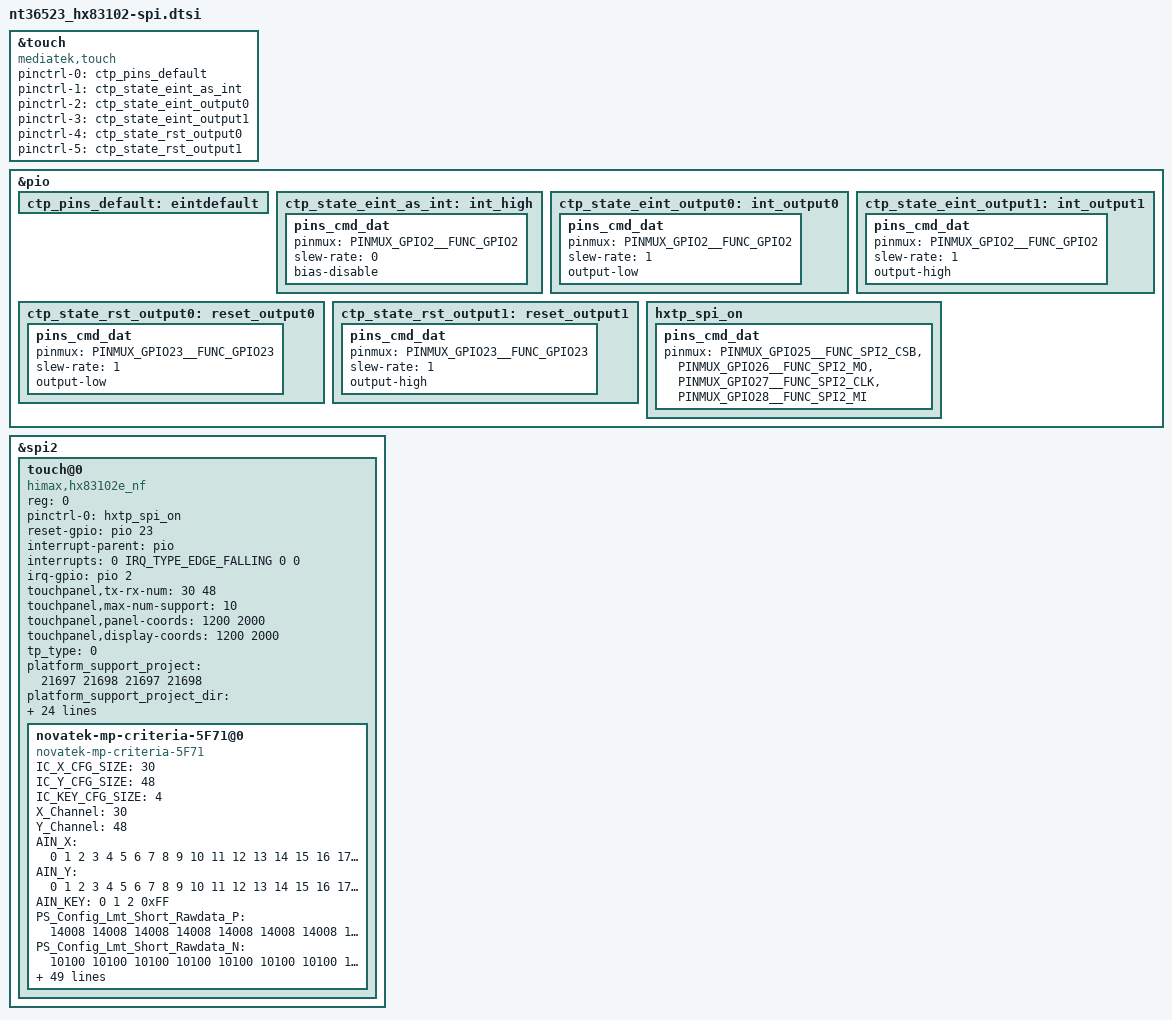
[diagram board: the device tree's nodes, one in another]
/*
 * Copyright (C) 2010 - 2021 Novatek, Inc.
 *
 * $Revision$
 * $Date$
 *
 * This program is free software; you can redistribute it and/or modify
 * it under the terms of the GNU General Public License as published by
 * the Free Software Foundation; either version 2 of the License, or
 * (at your option) any later version.
 *
 * This program is distributed in the hope that it will be useful, but WITHOUT
 * ANY WARRANTY; without even the implied warranty of MERCHANTABILITY or
 * FITNESS FOR A PARTICULAR PURPOSE.  See the GNU General Public License for
 * more details.
 *
 */

&touch {
	compatible = "mediatek,touch";

	pinctrl-names = "default", "state_eint_as_int",
	"state_eint_output0", "state_eint_output1",
	"state_rst_output0", "state_rst_output1";
	pinctrl-0 = <&ctp_pins_default>;
	pinctrl-1 = <&ctp_state_eint_as_int>;
	pinctrl-2 = <&ctp_state_eint_output0>;
	pinctrl-3 = <&ctp_state_eint_output1>;
	pinctrl-4 = <&ctp_state_rst_output0>;
	pinctrl-5 = <&ctp_state_rst_output1>;

};

&pio {

	ctp_pins_default: eintdefault {
	};
	ctp_state_eint_as_int: int_high {
		pins_cmd_dat {
			pinmux = <PINMUX_GPIO2__FUNC_GPIO2>;
			slew-rate = <0>;
			bias-disable;
		};
	};
	ctp_state_eint_output0: int_output0 {
		pins_cmd_dat {
			pinmux = <PINMUX_GPIO2__FUNC_GPIO2>;
			slew-rate = <1>;
			output-low;
		};
	};
	ctp_state_eint_output1: int_output1 {
		pins_cmd_dat {
			pinmux = <PINMUX_GPIO2__FUNC_GPIO2>;
			slew-rate = <1>;
			output-high;
		};
	};
	ctp_state_rst_output0: reset_output0 {
		pins_cmd_dat {
			pinmux = <PINMUX_GPIO23__FUNC_GPIO23>;
			slew-rate = <1>;
			output-low;
		};
	};
	ctp_state_rst_output1: reset_output1 {
		pins_cmd_dat {
			pinmux = <PINMUX_GPIO23__FUNC_GPIO23>;
			slew-rate = <1>;
			output-high;
		};
	};

	hxtp_spi_on:hxtp_spi_on {
	    pins_cmd_dat {
			pinmux = <PINMUX_GPIO25__FUNC_SPI2_CSB>,
			         <PINMUX_GPIO26__FUNC_SPI2_MO>,
					 <PINMUX_GPIO27__FUNC_SPI2_CLK>,
					 <PINMUX_GPIO28__FUNC_SPI2_MI>;

		};
    };
};

&spi2 {
	status = "ok";

	touch@0 {
		compatible = "himax,hx83102e_nf", "novatek,nf_nt36523";

		reg = <0>; //Same as CS ID
		status = "ok";

		/* Himax device*/
		pinctrl-names = "state_spi_all";
		pinctrl-0 = <&hxtp_spi_on>;

		/* Novatek device tree node */
		reset-gpio = <&pio 23 0>;
		interrupt-parent = <&pio>;
		interrupts = <0 IRQ_TYPE_EDGE_FALLING 0 0>; //1 IRQ_TYPE_EDGE_FALLING 1 0
		irq-gpio = <&pio 2 2>;
        //  lcd-reset-gpio = <&pio 44 0>;
		touchpanel,tx-rx-num = <30 48>;
		touchpanel,max-num-support = <10>;
		touchpanel,panel-coords = <1200 2000>;
		touchpanel,display-coords = <1200 2000>;
		//touchpanel,touchmajor-limit = <0 54>;
		tp_type = <0>;
		platform_support_project = <21697 21698 21697 21698>;
		platform_support_project_dir = <21697 21698 21697 21698>;
		platform_support_project_commandline = "nt36523b_hdp_dsi_vdo_dijing","nt36523b_hdp_dsi_vdo_dijing", "hx83_hdp_dsi_vdo_txd", "hx83_hdp_dsi_vdo_txd";
		chip_name = "NT36525B";

		spi-max-frequency = <10000000>;

		incell_screen;
		//fw_edge_limit_support;
		black_gesture_support;
		new_set_irq_wake_support;
		charger_pump_support;
		headset_pump_support;
		//esd_handle_support;
		//spurious_fingerprint_support;
		lcd_trigger_fp_check;
		black_gesture_test_support;
		noflash_support;
		smart_gesture_support;
		//pressure_report_support;
		fw_update_app_support;
		game_switch_support;
		//drlimit_remove_support;
		lcd_trigger_load_tp_fw_support;
		fw_update_in_probe_with_headfile;
		touchpanel,button-type = <4>;
		spi_fast_read_support;

		/* 525 */
		//novatek,swrst-n8-addr = <0x01F01A>;

		/* 672A, 525B, 675, 526, 672C, 523 */
		novatek,swrst-n8-addr = <0x03F0FE>;
		novatek,spi-rd-fast-addr = <0x03F310>;

		/* MP */
		//novatek,mp-support-dt;

		/*for longcheer_P560_Realme 523B INX_DJN10.36" module*/
		novatek-mp-criteria-5F71@0 {
			#address-cells = <1>;
			#size-cells = <0>;
			compatible = "novatek-mp-criteria-5F71";

			/* MP Config */
			IC_X_CFG_SIZE = <30>;
			IC_Y_CFG_SIZE = <48>;
			IC_KEY_CFG_SIZE = <4>;
			X_Channel = <30>;
			Y_Channel = <48>;

			AIN_X = <0 1 2 3 4 5 6 7 8 9 10 11 12 13 14 15 16 17 18 19 20 21 22 23 24 25 26 27 28 29>;
			AIN_Y = <0 1 2 3 4 5 6 7 8 9 10 11 12 13 14 15 16 17 18 19 20 21 22 23 24 25 26 27 28 29 30 31 32 33 34 35 36 37 38 39 40 41 42 43 44 45 46 47>;
			AIN_KEY = <0 1 2 0xFF>;

			/* MP Criteria */
			PS_Config_Lmt_Short_Rawdata_P = <
				14008 14008 14008 14008 14008 14008 14008 14008 14008 14008 14008 14008 14008 14008 14008 14008 14008 14008 14008 14008 14008 14008 14008 14008 14008 14008 14008 14008 14008 14008
				14008 14008 14008 14008 14008 14008 14008 14008 14008 14008 14008 14008 14008 14008 14008 14008 14008 14008 14008 14008 14008 14008 14008 14008 14008 14008 14008 14008 14008 14008
				14008 14008 14008 14008 14008 14008 14008 14008 14008 14008 14008 14008 14008 14008 14008 14008 14008 14008 14008 14008 14008 14008 14008 14008 14008 14008 14008 14008 14008 14008
				14008 14008 14008 14008 14008 14008 14008 14008 14008 14008 14008 14008 14008 14008 14008 14008 14008 14008 14008 14008 14008 14008 14008 14008 14008 14008 14008 14008 14008 14008
				14008 14008 14008 14008 14008 14008 14008 14008 14008 14008 14008 14008 14008 14008 14008 14008 14008 14008 14008 14008 14008 14008 14008 14008 14008 14008 14008 14008 14008 14008
				14008 14008 14008 14008 14008 14008 14008 14008 14008 14008 14008 14008 14008 14008 14008 14008 14008 14008 14008 14008 14008 14008 14008 14008 14008 14008 14008 14008 14008 14008
				14008 14008 14008 14008 14008 14008 14008 14008 14008 14008 14008 14008 14008 14008 14008 14008 14008 14008 14008 14008 14008 14008 14008 14008 14008 14008 14008 14008 14008 14008
				14008 14008 14008 14008 14008 14008 14008 14008 14008 14008 14008 14008 14008 14008 14008 14008 14008 14008 14008 14008 14008 14008 14008 14008 14008 14008 14008 14008 14008 14008
				14008 14008 14008 14008 14008 14008 14008 14008 14008 14008 14008 14008 14008 14008 14008 14008 14008 14008 14008 14008 14008 14008 14008 14008 14008 14008 14008 14008 14008 14008
				14008 14008 14008 14008 14008 14008 14008 14008 14008 14008 14008 14008 14008 14008 14008 14008 14008 14008 14008 14008 14008 14008 14008 14008 14008 14008 14008 14008 14008 14008
				14008 14008 14008 14008 14008 14008 14008 14008 14008 14008 14008 14008 14008 14008 14008 14008 14008 14008 14008 14008 14008 14008 14008 14008 14008 14008 14008 14008 14008 14008
				14008 14008 14008 14008 14008 14008 14008 14008 14008 14008 14008 14008 14008 14008 14008 14008 14008 14008 14008 14008 14008 14008 14008 14008 14008 14008 14008 14008 14008 14008
				14008 14008 14008 14008 14008 14008 14008 14008 14008 14008 14008 14008 14008 14008 14008 14008 14008 14008 14008 14008 14008 14008 14008 14008 14008 14008 14008 14008 14008 14008
				14008 14008 14008 14008 14008 14008 14008 14008 14008 14008 14008 14008 14008 14008 14008 14008 14008 14008 14008 14008 14008 14008 14008 14008 14008 14008 14008 14008 14008 14008
				14008 14008 14008 14008 14008 14008 14008 14008 14008 14008 14008 14008 14008 14008 14008 14008 14008 14008 14008 14008 14008 14008 14008 14008 14008 14008 14008 14008 14008 14008
				14008 14008 14008 14008 14008 14008 14008 14008 14008 14008 14008 14008 14008 14008 14008 14008 14008 14008 14008 14008 14008 14008 14008 14008 14008 14008 14008 14008 14008 14008
				14008 14008 14008 14008 14008 14008 14008 14008 14008 14008 14008 14008 14008 14008 14008 14008 14008 14008 14008 14008 14008 14008 14008 14008 14008 14008 14008 14008 14008 14008
				14008 14008 14008 14008 14008 14008 14008 14008 14008 14008 14008 14008 14008 14008 14008 14008 14008 14008 14008 14008 14008 14008 14008 14008 14008 14008 14008 14008 14008 14008
				14008 14008 14008 14008 14008 14008 14008 14008 14008 14008 14008 14008 14008 14008 14008 14008 14008 14008 14008 14008 14008 14008 14008 14008 14008 14008 14008 14008 14008 14008
				14008 14008 14008 14008 14008 14008 14008 14008 14008 14008 14008 14008 14008 14008 14008 14008 14008 14008 14008 14008 14008 14008 14008 14008 14008 14008 14008 14008 14008 14008
				14008 14008 14008 14008 14008 14008 14008 14008 14008 14008 14008 14008 14008 14008 14008 14008 14008 14008 14008 14008 14008 14008 14008 14008 14008 14008 14008 14008 14008 14008
				14008 14008 14008 14008 14008 14008 14008 14008 14008 14008 14008 14008 14008 14008 14008 14008 14008 14008 14008 14008 14008 14008 14008 14008 14008 14008 14008 14008 14008 14008
				14008 14008 14008 14008 14008 14008 14008 14008 14008 14008 14008 14008 14008 14008 14008 14008 14008 14008 14008 14008 14008 14008 14008 14008 14008 14008 14008 14008 14008 14008
				14008 14008 14008 14008 14008 14008 14008 14008 14008 14008 14008 14008 14008 14008 14008 14008 14008 14008 14008 14008 14008 14008 14008 14008 14008 14008 14008 14008 14008 14008
				14008 14008 14008 14008 14008 14008 14008 14008 14008 14008 14008 14008 14008 14008 14008 14008 14008 14008 14008 14008 14008 14008 14008 14008 14008 14008 14008 14008 14008 14008
				14008 14008 14008 14008 14008 14008 14008 14008 14008 14008 14008 14008 14008 14008 14008 14008 14008 14008 14008 14008 14008 14008 14008 14008 14008 14008 14008 14008 14008 14008
				14008 14008 14008 14008 14008 14008 14008 14008 14008 14008 14008 14008 14008 14008 14008 14008 14008 14008 14008 14008 14008 14008 14008 14008 14008 14008 14008 14008 14008 14008
				14008 14008 14008 14008 14008 14008 14008 14008 14008 14008 14008 14008 14008 14008 14008 14008 14008 14008 14008 14008 14008 14008 14008 14008 14008 14008 14008 14008 14008 14008
				14008 14008 14008 14008 14008 14008 14008 14008 14008 14008 14008 14008 14008 14008 14008 14008 14008 14008 14008 14008 14008 14008 14008 14008 14008 14008 14008 14008 14008 14008
				14008 14008 14008 14008 14008 14008 14008 14008 14008 14008 14008 14008 14008 14008 14008 14008 14008 14008 14008 14008 14008 14008 14008 14008 14008 14008 14008 14008 14008 14008
				14008 14008 14008 14008 14008 14008 14008 14008 14008 14008 14008 14008 14008 14008 14008 14008 14008 14008 14008 14008 14008 14008 14008 14008 14008 14008 14008 14008 14008 14008
				14008 14008 14008 14008 14008 14008 14008 14008 14008 14008 14008 14008 14008 14008 14008 14008 14008 14008 14008 14008 14008 14008 14008 14008 14008 14008 14008 14008 14008 14008
				14008 14008 14008 14008 14008 14008 14008 14008 14008 14008 14008 14008 14008 14008 14008 14008 14008 14008 14008 14008 14008 14008 14008 14008 14008 14008 14008 14008 14008 14008
				14008 14008 14008 14008 14008 14008 14008 14008 14008 14008 14008 14008 14008 14008 14008 14008 14008 14008 14008 14008 14008 14008 14008 14008 14008 14008 14008 14008 14008 14008
				14008 14008 14008 14008 14008 14008 14008 14008 14008 14008 14008 14008 14008 14008 14008 14008 14008 14008 14008 14008 14008 14008 14008 14008 14008 14008 14008 14008 14008 14008
				14008 14008 14008 14008 14008 14008 14008 14008 14008 14008 14008 14008 14008 14008 14008 14008 14008 14008 14008 14008 14008 14008 14008 14008 14008 14008 14008 14008 14008 14008
				14008 14008 14008 14008 14008 14008 14008 14008 14008 14008 14008 14008 14008 14008 14008 14008 14008 14008 14008 14008 14008 14008 14008 14008 14008 14008 14008 14008 14008 14008
				14008 14008 14008 14008 14008 14008 14008 14008 14008 14008 14008 14008 14008 14008 14008 14008 14008 14008 14008 14008 14008 14008 14008 14008 14008 14008 14008 14008 14008 14008
				14008 14008 14008 14008 14008 14008 14008 14008 14008 14008 14008 14008 14008 14008 14008 14008 14008 14008 14008 14008 14008 14008 14008 14008 14008 14008 14008 14008 14008 14008
				14008 14008 14008 14008 14008 14008 14008 14008 14008 14008 14008 14008 14008 14008 14008 14008 14008 14008 14008 14008 14008 14008 14008 14008 14008 14008 14008 14008 14008 14008
				14008 14008 14008 14008 14008 14008 14008 14008 14008 14008 14008 14008 14008 14008 14008 14008 14008 14008 14008 14008 14008 14008 14008 14008 14008 14008 14008 14008 14008 14008
				14008 14008 14008 14008 14008 14008 14008 14008 14008 14008 14008 14008 14008 14008 14008 14008 14008 14008 14008 14008 14008 14008 14008 14008 14008 14008 14008 14008 14008 14008
				14008 14008 14008 14008 14008 14008 14008 14008 14008 14008 14008 14008 14008 14008 14008 14008 14008 14008 14008 14008 14008 14008 14008 14008 14008 14008 14008 14008 14008 14008
				14008 14008 14008 14008 14008 14008 14008 14008 14008 14008 14008 14008 14008 14008 14008 14008 14008 14008 14008 14008 14008 14008 14008 14008 14008 14008 14008 14008 14008 14008
				14008 14008 14008 14008 14008 14008 14008 14008 14008 14008 14008 14008 14008 14008 14008 14008 14008 14008 14008 14008 14008 14008 14008 14008 14008 14008 14008 14008 14008 14008
				14008 14008 14008 14008 14008 14008 14008 14008 14008 14008 14008 14008 14008 14008 14008 14008 14008 14008 14008 14008 14008 14008 14008 14008 14008 14008 14008 14008 14008 14008
				14008 14008 14008 14008 14008 14008 14008 14008 14008 14008 14008 14008 14008 14008 14008 14008 14008 14008 14008 14008 14008 14008 14008 14008 14008 14008 14008 14008 14008 14008
				14008 14008 14008 14008 14008 14008 14008 14008 14008 14008 14008 14008 14008 14008 14008 14008 14008 14008 14008 14008 14008 14008 14008 14008 14008 14008 14008 14008 14008 14008
				14008 14008 14008>;

			PS_Config_Lmt_Short_Rawdata_N = <
				10100 10100 10100 10100 10100 10100 10100 10100 10100 10100 10100 10100 10100 10100 10100 10100 10100 10100 10100 10100 10100 10100 10100 10100 10100 10100 10100 10100 10100 10100
				10100 10100 10100 10100 10100 10100 10100 10100 10100 10100 10100 10100 10100 10100 10100 10100 10100 10100 10100 10100 10100 10100 10100 10100 10100 10100 10100 10100 10100 10100
				10100 10100 10100 10100 10100 10100 10100 10100 10100 10100 10100 10100 10100 10100 10100 10100 10100 10100 10100 10100 10100 10100 10100 10100 10100 10100 10100 10100 10100 10100
				10100 10100 10100 10100 10100 10100 10100 10100 10100 10100 10100 10100 10100 10100 10100 10100 10100 10100 10100 10100 10100 10100 10100 10100 10100 10100 10100 10100 10100 10100
				10100 10100 10100 10100 10100 10100 10100 10100 10100 10100 10100 10100 10100 10100 10100 10100 10100 10100 10100 10100 10100 10100 10100 10100 10100 10100 10100 10100 10100 10100
				10100 10100 10100 10100 10100 10100 10100 10100 10100 10100 10100 10100 10100 10100 10100 10100 10100 10100 10100 10100 10100 10100 10100 10100 10100 10100 10100 10100 10100 10100
				10100 10100 10100 10100 10100 10100 10100 10100 10100 10100 10100 10100 10100 10100 10100 10100 10100 10100 10100 10100 10100 10100 10100 10100 10100 10100 10100 10100 10100 10100
				10100 10100 10100 10100 10100 10100 10100 10100 10100 10100 10100 10100 10100 10100 10100 10100 10100 10100 10100 10100 10100 10100 10100 10100 10100 10100 10100 10100 10100 10100
				10100 10100 10100 10100 10100 10100 10100 10100 10100 10100 10100 10100 10100 10100 10100 10100 10100 10100 10100 10100 10100 10100 10100 10100 10100 10100 10100 10100 10100 10100
				10100 10100 10100 10100 10100 10100 10100 10100 10100 10100 10100 10100 10100 10100 10100 10100 10100 10100 10100 10100 10100 10100 10100 10100 10100 10100 10100 10100 10100 10100
				10100 10100 10100 10100 10100 10100 10100 10100 10100 10100 10100 10100 10100 10100 10100 10100 10100 10100 10100 10100 10100 10100 10100 10100 10100 10100 10100 10100 10100 10100
				10100 10100 10100 10100 10100 10100 10100 10100 10100 10100 10100 10100 10100 10100 10100 10100 10100 10100 10100 10100 10100 10100 10100 10100 10100 10100 10100 10100 10100 10100
				10100 10100 10100 10100 10100 10100 10100 10100 10100 10100 10100 10100 10100 10100 10100 10100 10100 10100 10100 10100 10100 10100 10100 10100 10100 10100 10100 10100 10100 10100
				10100 10100 10100 10100 10100 10100 10100 10100 10100 10100 10100 10100 10100 10100 10100 10100 10100 10100 10100 10100 10100 10100 10100 10100 10100 10100 10100 10100 10100 10100
				10100 10100 10100 10100 10100 10100 10100 10100 10100 10100 10100 10100 10100 10100 10100 10100 10100 10100 10100 10100 10100 10100 10100 10100 10100 10100 10100 10100 10100 10100
				10100 10100 10100 10100 10100 10100 10100 10100 10100 10100 10100 10100 10100 10100 10100 10100 10100 10100 10100 10100 10100 10100 10100 10100 10100 10100 10100 10100 10100 10100
				10100 10100 10100 10100 10100 10100 10100 10100 10100 10100 10100 10100 10100 10100 10100 10100 10100 10100 10100 10100 10100 10100 10100 10100 10100 10100 10100 10100 10100 10100
				10100 10100 10100 10100 10100 10100 10100 10100 10100 10100 10100 10100 10100 10100 10100 10100 10100 10100 10100 10100 10100 10100 10100 10100 10100 10100 10100 10100 10100 10100
				10100 10100 10100 10100 10100 10100 10100 10100 10100 10100 10100 10100 10100 10100 10100 10100 10100 10100 10100 10100 10100 10100 10100 10100 10100 10100 10100 10100 10100 10100
				10100 10100 10100 10100 10100 10100 10100 10100 10100 10100 10100 10100 10100 10100 10100 10100 10100 10100 10100 10100 10100 10100 10100 10100 10100 10100 10100 10100 10100 10100
				10100 10100 10100 10100 10100 10100 10100 10100 10100 10100 10100 10100 10100 10100 10100 10100 10100 10100 10100 10100 10100 10100 10100 10100 10100 10100 10100 10100 10100 10100
				10100 10100 10100 10100 10100 10100 10100 10100 10100 10100 10100 10100 10100 10100 10100 10100 10100 10100 10100 10100 10100 10100 10100 10100 10100 10100 10100 10100 10100 10100
				10100 10100 10100 10100 10100 10100 10100 10100 10100 10100 10100 10100 10100 10100 10100 10100 10100 10100 10100 10100 10100 10100 10100 10100 10100 10100 10100 10100 10100 10100
				10100 10100 10100 10100 10100 10100 10100 10100 10100 10100 10100 10100 10100 10100 10100 10100 10100 10100 10100 10100 10100 10100 10100 10100 10100 10100 10100 10100 10100 10100
				10100 10100 10100 10100 10100 10100 10100 10100 10100 10100 10100 10100 10100 10100 10100 10100 10100 10100 10100 10100 10100 10100 10100 10100 10100 10100 10100 10100 10100 10100
				10100 10100 10100 10100 10100 10100 10100 10100 10100 10100 10100 10100 10100 10100 10100 10100 10100 10100 10100 10100 10100 10100 10100 10100 10100 10100 10100 10100 10100 10100
				10100 10100 10100 10100 10100 10100 10100 10100 10100 10100 10100 10100 10100 10100 10100 10100 10100 10100 10100 10100 10100 10100 10100 10100 10100 10100 10100 10100 10100 10100
				10100 10100 10100 10100 10100 10100 10100 10100 10100 10100 10100 10100 10100 10100 10100 10100 10100 10100 10100 10100 10100 10100 10100 10100 10100 10100 10100 10100 10100 10100
				10100 10100 10100 10100 10100 10100 10100 10100 10100 10100 10100 10100 10100 10100 10100 10100 10100 10100 10100 10100 10100 10100 10100 10100 10100 10100 10100 10100 10100 10100
				10100 10100 10100 10100 10100 10100 10100 10100 10100 10100 10100 10100 10100 10100 10100 10100 10100 10100 10100 10100 10100 10100 10100 10100 10100 10100 10100 10100 10100 10100
				10100 10100 10100 10100 10100 10100 10100 10100 10100 10100 10100 10100 10100 10100 10100 10100 10100 10100 10100 10100 10100 10100 10100 10100 10100 10100 10100 10100 10100 10100
				10100 10100 10100 10100 10100 10100 10100 10100 10100 10100 10100 10100 10100 10100 10100 10100 10100 10100 10100 10100 10100 10100 10100 10100 10100 10100 10100 10100 10100 10100
				10100 10100 10100 10100 10100 10100 10100 10100 10100 10100 10100 10100 10100 10100 10100 10100 10100 10100 10100 10100 10100 10100 10100 10100 10100 10100 10100 10100 10100 10100
				10100 10100 10100 10100 10100 10100 10100 10100 10100 10100 10100 10100 10100 10100 10100 10100 10100 10100 10100 10100 10100 10100 10100 10100 10100 10100 10100 10100 10100 10100
				10100 10100 10100 10100 10100 10100 10100 10100 10100 10100 10100 10100 10100 10100 10100 10100 10100 10100 10100 10100 10100 10100 10100 10100 10100 10100 10100 10100 10100 10100
				10100 10100 10100 10100 10100 10100 10100 10100 10100 10100 10100 10100 10100 10100 10100 10100 10100 10100 10100 10100 10100 10100 10100 10100 10100 10100 10100 10100 10100 10100
				10100 10100 10100 10100 10100 10100 10100 10100 10100 10100 10100 10100 10100 10100 10100 10100 10100 10100 10100 10100 10100 10100 10100 10100 10100 10100 10100 10100 10100 10100
				10100 10100 10100 10100 10100 10100 10100 10100 10100 10100 10100 10100 10100 10100 10100 10100 10100 10100 10100 10100 10100 10100 10100 10100 10100 10100 10100 10100 10100 10100
				10100 10100 10100 10100 10100 10100 10100 10100 10100 10100 10100 10100 10100 10100 10100 10100 10100 10100 10100 10100 10100 10100 10100 10100 10100 10100 10100 10100 10100 10100
				10100 10100 10100 10100 10100 10100 10100 10100 10100 10100 10100 10100 10100 10100 10100 10100 10100 10100 10100 10100 10100 10100 10100 10100 10100 10100 10100 10100 10100 10100
				10100 10100 10100 10100 10100 10100 10100 10100 10100 10100 10100 10100 10100 10100 10100 10100 10100 10100 10100 10100 10100 10100 10100 10100 10100 10100 10100 10100 10100 10100
				10100 10100 10100 10100 10100 10100 10100 10100 10100 10100 10100 10100 10100 10100 10100 10100 10100 10100 10100 10100 10100 10100 10100 10100 10100 10100 10100 10100 10100 10100
				10100 10100 10100 10100 10100 10100 10100 10100 10100 10100 10100 10100 10100 10100 10100 10100 10100 10100 10100 10100 10100 10100 10100 10100 10100 10100 10100 10100 10100 10100
				10100 10100 10100 10100 10100 10100 10100 10100 10100 10100 10100 10100 10100 10100 10100 10100 10100 10100 10100 10100 10100 10100 10100 10100 10100 10100 10100 10100 10100 10100
				10100 10100 10100 10100 10100 10100 10100 10100 10100 10100 10100 10100 10100 10100 10100 10100 10100 10100 10100 10100 10100 10100 10100 10100 10100 10100 10100 10100 10100 10100
				10100 10100 10100 10100 10100 10100 10100 10100 10100 10100 10100 10100 10100 10100 10100 10100 10100 10100 10100 10100 10100 10100 10100 10100 10100 10100 10100 10100 10100 10100
				10100 10100 10100 10100 10100 10100 10100 10100 10100 10100 10100 10100 10100 10100 10100 10100 10100 10100 10100 10100 10100 10100 10100 10100 10100 10100 10100 10100 10100 10100
				10100 10100 10100 10100 10100 10100 10100 10100 10100 10100 10100 10100 10100 10100 10100 10100 10100 10100 10100 10100 10100 10100 10100 10100 10100 10100 10100 10100 10100 10100
				10100 10100 10100>;

			PS_Config_Lmt_Open_Rawdata_P = <
				3719	3725	3752	3743	3840	3774	3698	3634	3423	3539	3518	3518	3621	3743	3775	3673	3572	3586	3596	3704	3662	3592	3493	3340	3407	3448	3439	3514	3634	3570
				3816	3777	3759	3798	3735	3627	3599	3556	3329	3400	3458	3511	3617	3633	3621	3655	3605	3612	3655	3588	3528	3484	3441	3227	3333	3367	3434	3519	3575	3544
				3929	3823	3715	3788	3763	3820	3768	3693	3465	3577	3623	3620	3628	3739	3747	3771	3677	3572	3628	3623	3689	3663	3589	3362	3488	3493	3550	3557	3638	3638
				3857	3810	3777	3808	3827	3724	3630	3605	3382	3480	3487	3560	3624	3752	3553	3708	3668	3612	3665	3693	3585	3536	3487	3285	3381	3425	3470	3550	3654	3512
				4008	3892	3785	3652	3780	3715	3789	3739	3438	3588	3634	3694	3704	3718	3739	3834	3754	3651	3515	3627	3586	3662	3635	3341	3491	3544	3563	3637	3648	3642
				3875	3827	3773	3719	3809	3796	3704	3522	3424	3494	3533	3547	3642	3620	3747	3704	3691	3641	3561	3673	3668	3572	3431	3325	3403	3432	3490	3557	3571	3654
				3838	3914	3815	3684	3571	3704	3654	3652	3364	3515	3600	3659	3742	3696	3684	3670	3761	3691	3564	3445	3563	3529	3553	3301	3420	3511	3572	3616	3633	3621
				3957	3795	3747	3673	3631	3724	3719	3633	3445	3508	3519	3570	3603	3694	3677	3810	3647	3627	3554	3486	3603	3602	3507	3367	3410	3428	3467	3551	3617	3610
				3875	3854	3918	3795	3676	3441	3589	3669	3479	3521	3614	3714	3649	3876	3788	3719	3698	3775	3673	3563	3320	3456	3544	3361	3459	3523	3621	3574	3753	3735
				3973	3976	3796	3726	3659	3602	3715	3739	3451	3607	3606	3626	3673	3736	3721	3820	3845	3659	3610	3547	3459	3605	3617	3337	3530	3511	3537	3567	3683	3649
				3913	3859	3815	3855	3698	3633	3536	3697	3570	3598	3586	3647	3798	3887	3851	3732	3721	3676	3722	3581	3525	3423	3565	3469	3484	3525	3539	3712	3813	3732
				3938	3962	3939	3736	3572	3621	3596	3722	3483	3571	3669	3574	3712	3788	3712	3782	3822	3817	3606	3476	3518	3463	3606	3385	3462	3600	3465	3630	3694	3661
				3896	3855	3782	3717	3770	3658	3565	3388	3535	3645	3619	3614	3733	3851	3813	3707	3693	3652	3588	3647	3561	3463	3278	3451	3550	3511	3561	3648	3777	3749
				3858	3887	3885	3749	3648	3596	3551	3397	3455	3557	3505	3698	3725	3766	3724	3708	3756	3763	3634	3530	3504	3459	3294	3378	3463	3410	3634	3641	3693	3637
				3983	3941	3862	3701	3718	3777	3679	3425	3565	3689	3704	3735	3747	3872	3868	3824	3761	3705	3579	3592	3659	3585	3330	3459	3609	3595	3627	3698	3792	3798
				3929	3901	3890	3872	3840	3651	3614	3521	3578	3605	3675	3719	3833	3865	3781	3774	3764	3767	3754	3735	3535	3525	3378	3474	3533	3585	3616	3774	3785	3710
				4065	3991	3781	3815	3731	3675	3746	3484	3571	3553	3771	3836	3824	3843	3833	3906	3848	3600	3662	3607	3551	3635	3383	3474	3445	3690	3752	3722	3803	3761
				3939	3943	3854	3840	3830	3795	3626	3467	3662	3687	3683	3747	3802	3935	3827	3780	3802	3739	3725	3722	3698	3515	3332	3523	3588	3613	3661	3705	3879	3752
				4034	3978	3913	3805	3729	3647	3616	3518	3540	3641	3721	3798	3886	3872	3761	3875	3824	3781	3644	3585	3530	3493	3420	3437	3556	3624	3725	3806	3781	3729
				3910	3801	3871	3771	3763	3750	3728	3424	3458	3733	3724	3712	3799	3851	3847	3775	3655	3739	3652	3655	3647	3641	3350	3320	3605	3624	3649	3719	3766	3798
				3962	4106	4040	3907	3813	3742	3675	3599	3708	3743	3760	3841	3938	4002	3865	3792	3956	3899	3780	3659	3602	3563	3487	3620	3649	3673	3745	3875	3925	3784
				4011	3978	3920	3859	3775	3773	3777	3418	3620	3735	3859	3851	3850	3917	3854	3820	3858	3784	3736	3666	3669	3673	3319	3544	3598	3732	3752	3792	3843	3777
				3988	3994	4072	3981	3869	3780	3724	3563	3761	3833	3820	3840	3935	4008	3963	3805	3841	3934	3850	3752	3630	3586	3459	3652	3747	3733	3756	3841	3953	3893
				4026	4151	3946	3873	3826	3743	3745	3543	3668	3736	3806	3936	3943	3917	3862	3844	3956	3840	3749	3710	3642	3648	3432	3564	3668	3672	3813	3852	3864	3795
				4085	4053	3963	4013	3935	3824	3747	3588	3771	3873	3903	3893	3932	3997	3953	3906	3887	3822	3880	3808	3712	3606	3480	3679	3771	3823	3808	3854	3911	3907
				4006	4036	4116	3886	3822	3774	3707	3599	3687	3777	3802	3873	4026	3991	3857	3836	3868	3935	3785	3704	3668	3614	3505	3582	3680	3735	3745	3904	3904	3813
				4134	4103	4047	3900	3969	3892	3798	3581	3736	3878	3943	3971	3974	3976	3886	3959	3948	3896	3767	3845	3774	3694	3483	3633	3795	3840	3899	3897	3904	3813
				4033	4027	4023	4050	3843	3780	3749	3662	3752	3795	3841	3868	3953	4076	3824	3857	3878	3868	3879	3752	3676	3648	3564	3662	3696	3746	3810	3824	3966	3782
				4148	4107	4047	3935	3806	3876	3810	3540	3689	3801	3900	3966	3999	3976	3883	3948	3955	3906	3794	3689	3766	3710	3463	3602	3704	3822	3871	3934	3901	3824
				3987	4009	3977	3924	3955	3750	3616	3668	3780	3822	3822	3872	3896	3847	3978	3831	3852	3843	3781	3798	3672	3494	3568	3686	3740	3726	3780	3847	3740	3883
				4041	4204	4165	4040	3932	3810	3841	3708	3746	3851	3927	4030	4096	4037	3971	3887	4020	4022	3906	3806	3700	3712	3613	3670	3767	3827	3949	4004	3969	3908
				4160	4055	4068	3969	3922	3959	3780	3628	3883	3946	3942	3946	3988	3992	3956	3997	3914	3918	3840	3788	3796	3710	3553	3781	3858	3869	3852	3899	3957	3845
				4069	4060	4209	4103	3999	3745	3789	3763	3875	3858	3918	3997	3950	4139	4046	3920	3922	4041	3967	3871	3623	3689	3668	3780	3787	3840	3901	3878	4057	4001
				4124	4176	4064	4006	3925	3876	3931	3631	3795	3995	4015	4009	4004	4039	3942	3925	4030	3935	3862	3803	3756	3782	3579	3718	3897	3935	3945	3918	3963	3915
				4075	4044	4019	4089	3945	3904	3810	3628	3880	3935	3872	3893	4005	4095	4040	3924	3921	3900	3932	3810	3788	3704	3522	3792	3848	3808	3810	3920	4030	3967
				4053	4102	4139	3953	3789	3838	3795	3543	3753	3854	4012	3903	4016	4008	3936	3889	3925	4011	3833	3655	3728	3691	3432	3711	3781	3918	3845	3962	3928	3872
				4191	4125	4104	4015	4099	4022	3922	3658	3836	4044	4057	3995	4046	4107	4095	3995	3997	3988	3904	3946	3904	3815	3549	3726	3960	3969	3936	3980	4029	4036
				4113	4121	4169	4037	3962	3925	3858	3641	3747	3906	3857	4151	4141	4106	4008	3946	3966	4004	3907	3848	3801	3752	3542	3637	3872	3815	4057	4074	4064	3936
				4243	4209	4135	3997	3970	4057	3978	3721	3901	3806	4057	4134	4041	4089	4057	4057	4025	4019	3885	3864	3915	3875	3617	3805	3735	3988	4050	3990	4033	3991
				4114	4123	4131	4107	4088	3927	3896	3658	3761	3789	3974	4040	4184	4187	4050	3941	3977	3985	3953	3977	3816	3780	3553	3669	3686	3942	3971	4099	4123	4020
				4244	4209	4015	4029	3960	3889	3959	3729	3677	3887	3893	4125	4120	4037	3990	4072	4047	3848	3924	3857	3789	3836	3627	3560	3802	3791	4051	4040	3990	3939
				4095	4089	4078	4039	4019	4008	3848	3654	3738	3767	3802	3988	4033	4186	4090	3931	3943	3952	3906	3879	3913	3747	3546	3672	3683	3705	3960	3971	4114	4037
				4298	4268	4281	4190	4044	3995	3914	3834	3858	3950	4022	4033	4233	4228	4043	4118	4088	4132	4027	3949	3900	3823	3710	3759	3834	3935	3932	4163	4158	4011
				4188	4064	4166	4110	4051	4048	4030	3722	3880	3848	3893	3934	4095	4139	4201	4001	3904	4030	3987	3929	3918	3943	3619	3784	3785	3809	3844	4067	4093	4139
				4187	4316	4323	4240	4146	4011	3956	3728	3869	3915	4025	4099	4137	4288	4179	4001	4162	4188	4100	3990	3920	3871	3638	3777	3813	3908	4022	4050	4221	4128
				4158	4214	4184	4128	4069	4020	4008	3854	3850	3934	3918	3970	4023	4141	4086	3957	4041	4044	4002	3955	3915	3889	3770	3775	3845	3855	3894	3957	4121	4057
				4123	4158	4274	4233	4144	4076	3922	3731	3876	3873	3932	4050	4144	4075	4186	3925	3998	4141	4109	4016	3925	3843	3644	3805	3785	3830	3941	4079	3998	4132
				3999	4240	4195	4111	4041	4005	3943	3785	3819	3851	3948	3950	4027	3974	4053	4013	4075	4026	3978	3931	3906	3848	3677	3733	3785	3869	3894	3964	3924	3878
				5120 5120 5120>;

			PS_Config_Lmt_Open_Rawdata_N = <
				1594	1596	1608	1604	1645	1617	1585	1557	1467	1516	1507	1507	1552	1604	1618	1574	1531	1537	1541	1587	1569	1539	1497	1431	1460	1477	1474	1506	1557	1530
				1635	1618	1611	1627	1600	1554	1542	1524	1426	1457	1482	1504	1550	1557	1552	1566	1545	1548	1566	1537	1512	1493	1474	1383	1428	1443	1471	1508	1532	1519
				1684	1638	1592	1623	1612	1637	1615	1582	1485	1533	1552	1551	1555	1602	1606	1616	1576	1531	1555	1552	1581	1570	1538	1441	1495	1497	1521	1524	1559	1559
				1653	1633	1618	1632	1640	1596	1555	1545	1449	1491	1494	1525	1553	1608	1522	1589	1572	1548	1570	1582	1536	1515	1494	1408	1449	1468	1487	1521	1566	1505
				1717	1668	1622	1565	1620	1592	1624	1602	1473	1537	1557	1583	1587	1593	1602	1643	1609	1564	1506	1554	1537	1569	1558	1432	1496	1519	1527	1558	1563	1561
				1660	1640	1617	1594	1632	1627	1587	1509	1467	1497	1514	1520	1561	1551	1606	1587	1582	1560	1526	1574	1572	1531	1470	1425	1458	1471	1495	1524	1530	1566
				1645	1677	1635	1579	1530	1587	1566	1565	1441	1506	1543	1568	1603	1584	1579	1573	1612	1582	1527	1476	1527	1512	1522	1414	1465	1504	1531	1549	1557	1552
				1696	1626	1606	1574	1556	1596	1594	1557	1476	1503	1508	1530	1544	1583	1576	1633	1563	1554	1523	1494	1544	1543	1503	1443	1461	1469	1486	1522	1550	1547
				1660	1651	1679	1626	1575	1474	1538	1572	1491	1509	1549	1591	1564	1661	1623	1594	1585	1618	1574	1527	1423	1481	1519	1440	1482	1510	1552	1531	1608	1600
				1702	1704	1627	1597	1568	1543	1592	1602	1479	1546	1545	1554	1574	1601	1594	1637	1648	1568	1547	1520	1482	1545	1550	1430	1513	1504	1516	1528	1578	1564
				1677	1654	1635	1652	1585	1557	1515	1584	1530	1542	1537	1563	1627	1666	1650	1599	1594	1575	1595	1534	1510	1467	1528	1486	1493	1510	1516	1591	1634	1599
				1687	1698	1688	1601	1531	1552	1541	1595	1492	1530	1572	1531	1591	1623	1591	1621	1638	1636	1545	1489	1507	1484	1545	1450	1483	1543	1485	1555	1583	1569
				1669	1652	1621	1593	1615	1567	1528	1452	1515	1562	1551	1549	1600	1650	1634	1588	1582	1565	1537	1563	1526	1484	1405	1479	1521	1504	1526	1563	1618	1606
				1653	1666	1665	1606	1563	1541	1522	1456	1480	1524	1502	1585	1596	1614	1596	1589	1609	1612	1557	1513	1501	1482	1411	1447	1484	1461	1557	1560	1582	1558
				1707	1689	1655	1586	1593	1618	1576	1468	1528	1581	1587	1600	1606	1659	1657	1639	1612	1588	1534	1539	1568	1536	1427	1482	1546	1540	1554	1585	1625	1627
				1684	1672	1667	1659	1645	1564	1549	1509	1533	1545	1575	1594	1642	1656	1620	1617	1613	1614	1609	1600	1515	1510	1447	1489	1514	1536	1549	1617	1622	1590
				1742	1710	1620	1635	1599	1575	1605	1493	1530	1522	1616	1644	1639	1647	1642	1674	1649	1543	1569	1546	1522	1558	1450	1489	1476	1581	1608	1595	1630	1612
				1688	1690	1651	1645	1641	1626	1554	1486	1569	1580	1578	1606	1629	1686	1640	1620	1629	1602	1596	1595	1585	1506	1428	1510	1537	1548	1569	1588	1662	1608
				1729	1705	1677	1630	1598	1563	1549	1507	1517	1560	1594	1627	1665	1659	1612	1660	1639	1620	1561	1536	1513	1497	1465	1473	1524	1553	1596	1631	1620	1598
				1675	1629	1659	1616	1612	1607	1597	1467	1482	1600	1596	1591	1628	1650	1648	1618	1566	1602	1565	1566	1563	1560	1435	1423	1545	1553	1564	1594	1614	1627
				1698	1759	1731	1674	1634	1603	1575	1542	1589	1604	1611	1646	1687	1715	1656	1625	1695	1671	1620	1568	1543	1527	1494	1551	1564	1574	1605	1660	1682	1621
				1719	1705	1680	1654	1618	1617	1618	1465	1551	1600	1654	1650	1650	1678	1651	1637	1653	1621	1601	1571	1572	1574	1422	1519	1542	1599	1608	1625	1647	1618
				1709	1711	1745	1706	1658	1620	1596	1527	1612	1642	1637	1645	1686	1717	1698	1630	1646	1686	1650	1608	1555	1537	1482	1565	1606	1600	1609	1646	1694	1668
				1725	1779	1691	1660	1639	1604	1605	1518	1572	1601	1631	1687	1690	1678	1655	1647	1695	1645	1606	1590	1561	1563	1471	1527	1572	1573	1634	1651	1656	1626
				1750	1737	1698	1720	1686	1639	1606	1537	1616	1660	1672	1668	1685	1713	1694	1674	1666	1638	1663	1632	1591	1545	1491	1576	1616	1638	1632	1651	1676	1674
				1717	1729	1764	1665	1638	1617	1588	1542	1580	1618	1629	1660	1725	1710	1653	1644	1657	1686	1622	1587	1572	1549	1502	1535	1577	1600	1605	1673	1673	1634
				1771	1758	1734	1671	1701	1668	1627	1534	1601	1662	1690	1702	1703	1704	1665	1696	1692	1669	1614	1648	1617	1583	1492	1557	1626	1645	1671	1670	1673	1634
				1728	1726	1724	1735	1647	1620	1606	1569	1608	1626	1646	1657	1694	1747	1639	1653	1662	1657	1662	1608	1575	1563	1527	1569	1584	1605	1633	1639	1699	1621
				1777	1760	1734	1686	1631	1661	1633	1517	1581	1629	1671	1699	1714	1704	1664	1692	1695	1674	1626	1581	1614	1590	1484	1543	1587	1638	1659	1686	1672	1639
				1708	1718	1704	1681	1695	1607	1549	1572	1620	1638	1638	1659	1669	1648	1705	1642	1651	1647	1620	1627	1573	1497	1529	1579	1603	1597	1620	1648	1603	1664
				1732	1801	1785	1731	1685	1633	1646	1589	1605	1650	1683	1727	1755	1730	1702	1666	1723	1723	1674	1631	1585	1591	1548	1573	1614	1640	1692	1716	1701	1675
				1783	1738	1743	1701	1681	1696	1620	1555	1664	1691	1689	1691	1709	1711	1695	1713	1677	1679	1645	1623	1627	1590	1522	1620	1653	1658	1651	1671	1696	1648
				1744	1740	1804	1758	1714	1605	1624	1612	1660	1653	1679	1713	1693	1774	1734	1680	1681	1732	1700	1659	1552	1581	1572	1620	1623	1645	1672	1662	1738	1714
				1767	1789	1741	1717	1682	1661	1684	1556	1626	1712	1720	1718	1716	1731	1689	1682	1727	1686	1655	1630	1609	1621	1534	1593	1670	1686	1690	1679	1698	1678
				1746	1733	1722	1752	1690	1673	1633	1555	1663	1686	1659	1668	1716	1755	1731	1681	1680	1671	1685	1633	1623	1587	1509	1625	1649	1632	1633	1680	1727	1700
				1737	1758	1774	1694	1624	1645	1626	1518	1608	1651	1719	1672	1721	1717	1687	1666	1682	1719	1642	1566	1597	1582	1471	1590	1620	1679	1648	1698	1683	1659
				1796	1768	1759	1720	1756	1723	1681	1567	1644	1733	1738	1712	1734	1760	1755	1712	1713	1709	1673	1691	1673	1635	1521	1597	1697	1701	1687	1705	1726	1729
				1762	1766	1786	1730	1698	1682	1653	1560	1606	1674	1653	1779	1774	1759	1717	1691	1699	1716	1674	1649	1629	1608	1518	1558	1659	1635	1738	1746	1741	1687
				1818	1804	1772	1713	1701	1738	1705	1594	1672	1631	1738	1771	1732	1752	1738	1738	1725	1722	1665	1656	1678	1660	1550	1630	1600	1709	1735	1710	1728	1710
				1763	1767	1770	1760	1752	1683	1669	1567	1612	1624	1703	1731	1793	1794	1735	1689	1704	1708	1694	1704	1635	1620	1522	1572	1579	1689	1702	1756	1767	1723
				1819	1804	1720	1726	1697	1666	1696	1598	1576	1666	1668	1768	1765	1730	1710	1745	1734	1649	1681	1653	1624	1644	1554	1525	1629	1624	1736	1731	1710	1688
				1755	1752	1747	1731	1722	1717	1649	1566	1602	1614	1629	1709	1728	1794	1753	1684	1690	1693	1674	1662	1677	1606	1519	1573	1578	1588	1697	1702	1763	1730
				1842	1829	1834	1795	1733	1712	1677	1643	1653	1693	1723	1728	1814	1812	1732	1765	1752	1771	1726	1692	1671	1638	1590	1611	1643	1686	1685	1784	1782	1719
				1795	1741	1785	1761	1736	1735	1727	1595	1663	1649	1668	1686	1755	1774	1800	1714	1673	1727	1708	1684	1679	1690	1551	1621	1622	1632	1647	1743	1754	1774
				1794	1849	1852	1817	1777	1719	1695	1597	1658	1678	1725	1756	1773	1837	1791	1714	1783	1795	1757	1710	1680	1659	1559	1618	1634	1675	1723	1735	1809	1769
				1782	1806	1793	1769	1744	1723	1717	1651	1650	1686	1679	1701	1724	1774	1751	1696	1732	1733	1715	1695	1678	1666	1615	1618	1648	1652	1669	1696	1766	1738
				1767	1782	1831	1814	1776	1747	1681	1599	1661	1660	1685	1735	1776	1746	1794	1682	1713	1774	1761	1721	1682	1647	1561	1630	1622	1641	1689	1748	1713	1771
				1714	1817	1798	1762	1732	1716	1690	1622	1636	1650	1692	1693	1726	1703	1737	1720	1746	1725	1705	1684	1674	1649	1576	1600	1622	1658	1669	1699	1681	1662>;

			PS_Config_Lmt_FW_Rawdata_P = <
				1110	1122	1125	1111	1124	1120	1129	1118	1125	1121	1125	1117	1114	1122	1113	1111	1113	1120	1118	1113	1134	1129	1110	1135	1117	1121	1117	1108	1120	1118
				1113	1121	1129	1117	1152	1125	1114	1114	1124	1104	1111	1118	1132	1120	1132	1124	1120	1111	1131	1125	1110	1134	1107	1124	1125	1136	1117	1132	1115	1117
				1118	1131	1128	1115	1118	1124	1129	1118	1122	1121	1110	1111	1120	1129	1121	1127	1121	1136	1138	1125	1135	1104	1117	1110	1108	1104	1108	1131	1125	1127
				1120	1120	1124	1110	1131	1114	1106	1115	1122	1120	1113	1121	1125	1136	1124	1120	1120	1118	1122	1138	1124	1106	1114	1115	1117	1134	1131	1117	1127	1124
				1120	1118	1128	1122	1125	1125	1128	1121	1121	1111	1117	1115	1111	1115	1108	1108	1127	1120	1128	1129	1121	1124	1128	1118	1117	1111	1111	1118	1114	1115
				1114	1118	1111	1129	1113	1124	1103	1124	1131	1125	1128	1122	1131	1125	1103	1124	1124	1121	1114	1136	1136	1121	1129	1120	1113	1114	1138	1115	1122	1106
				1131	1120	1115	1134	1122	1129	1113	1104	1096	1117	1121	1124	1124	1114	1111	1122	1111	1131	1124	1124	1125	1117	1113	1121	1127	1134	1118	1110	1121	1118
				1132	1108	1118	1121	1127	1114	1120	1120	1136	1134	1127	1121	1128	1125	1113	1113	1128	1121	1120	1114	1145	1121	1117	1122	1121	1127	1120	1128	1106	1129
				1113	1122	1128	1117	1135	1131	1129	1121	1122	1096	1117	1122	1127	1128	1125	1114	1125	1114	1131	1118	1127	1117	1117	1124	1125	1125	1138	1127	1122	1134
				1134	1131	1106	1122	1121	1125	1117	1122	1108	1120	1138	1121	1129	1135	1129	1128	1113	1127	1121	1117	1106	1138	1104	1131	1121	1125	1129	1120	1111	1117
				1115	1129	1128	1120	1118	1135	1120	1120	1120	1121	1101	1127	1129	1132	1134	1118	1117	1136	1114	1132	1121	1118	1113	1120	1132	1121	1121	1135	1141	1139
				1118	1127	1128	1115	1121	1120	1134	1136	1128	1115	1127	1134	1124	1127	1135	1113	1127	1114	1121	1122	1117	1115	1110	1118	1128	1117	1124	1124	1124	1111
				1118	1114	1132	1131	1118	1117	1125	1117	1114	1125	1121	1110	1114	1127	1129	1120	1122	1111	1135	1113	1134	1117	1122	1118	1115	1129	1122	1120	1117	1125
				1122	1132	1129	1122	1110	1120	1117	1124	1118	1136	1124	1127	1122	1121	1128	1128	1114	1120	1117	1124	1125	1121	1120	1113	1114	1132	1113	1124	1111	1131
				1127	1120	1111	1131	1134	1117	1115	1124	1134	1120	1128	1122	1111	1118	1125	1114	1122	1117	1121	1134	1114	1134	1120	1113	1117	1117	1122	1124	1114	1108
				1128	1124	1129	1134	1121	1107	1122	1129	1118	1122	1142	1125	1124	1110	1117	1117	1122	1110	1121	1115	1129	1125	1110	1113	1120	1117	1128	1106	1120	1111
				1124	1129	1114	1115	1134	1132	1117	1110	1122	1129	1117	1127	1125	1118	1115	1117	1118	1113	1118	1118	1131	1113	1124	1118	1117	1122	1131	1128	1124	1115
				1125	1131	1124	1124	1129	1122	1114	1125	1118	1120	1121	1124	1129	1107	1104	1120	1118	1131	1108	1118	1107	1131	1118	1132	1118	1120	1122	1115	1113	1115
				1121	1124	1129	1108	1120	1136	1117	1118	1118	1124	1129	1115	1124	1125	1120	1131	1121	1117	1111	1118	1118	1131	1118	1124	1128	1121	1127	1127	1127	1117
				1121	1131	1125	1121	1125	1135	1132	1129	1110	1121	1120	1115	1134	1129	1107	1124	1110	1117	1134	1108	1125	1111	1131	1124	1132	1124	1125	1115	1115	1118
				1113	1115	1124	1127	1111	1121	1134	1106	1124	1117	1122	1125	1115	1127	1125	1115	1128	1122	1117	1113	1117	1103	1129	1113	1129	1135	1124	1128	1135	1113
				1110	1121	1125	1127	1125	1128	1118	1115	1117	1108	1121	1120	1115	1131	1128	1121	1125	1113	1120	1129	1113	1120	1108	1118	1129	1121	1128	1131	1120	1108
				1122	1117	1118	1125	1124	1118	1124	1132	1115	1128	1122	1122	1113	1117	1120	1124	1118	1127	1125	1120	1110	1124	1118	1128	1121	1125	1132	1121	1132	1118
				1128	1110	1128	1122	1124	1127	1120	1115	1120	1120	1115	1117	1124	1115	1125	1120	1125	1129	1117	1122	1124	1121	1129	1128	1100	1134	1110	1129	1134	1125
				1121	1122	1117	1118	1124	1125	1113	1127	1117	1121	1131	1128	1111	1108	1115	1124	1121	1118	1127	1124	1124	1115	1111	1118	1115	1120	1127	1135	1121	1128
				1122	1125	1108	1124	1124	1124	1121	1121	1139	1118	1120	1118	1118	1127	1117	1128	1129	1128	1128	1106	1124	1114	1113	1118	1135	1108	1122	1101	1131	1129
				1121	1134	1124	1113	1118	1124	1124	1131	1115	1121	1121	1135	1128	1114	1107	1108	1127	1121	1121	1124	1121	1113	1124	1124	1124	1118	1125	1127	1129	1127
				1113	1121	1124	1115	1127	1125	1131	1113	1118	1139	1124	1117	1114	1113	1118	1124	1121	1125	1131	1128	1107	1128	1115	1111	1120	1136	1106	1117	1104	1128
				1129	1122	1128	1124	1124	1118	1124	1113	1113	1111	1121	1125	1131	1132	1113	1110	1107	1122	1127	1122	1127	1125	1127	1118	1117	1128	1115	1122	1129	1120
				1108	1111	1118	1122	1113	1122	1132	1107	1127	1117	1141	1122	1120	1120	1111	1121	1120	1114	1127	1128	1128	1114	1125	1135	1115	1117	1139	1107	1127	1106
				1125	1122	1122	1108	1122	1107	1122	1135	1111	1111	1113	1122	1124	1128	1129	1117	1113	1106	1125	1121	1127	1120	1125	1128	1111	1118	1124	1110	1120	1122
				1111	1114	1124	1122	1128	1118	1121	1111	1124	1128	1118	1136	1122	1122	1118	1122	1125	1118	1110	1121	1125	1118	1117	1108	1128	1115	1113	1132	1108	1117
				1129	1122	1122	1113	1110	1124	1108	1122	1122	1113	1118	1113	1124	1122	1128	1108	1120	1110	1103	1127	1121	1122	1125	1125	1124	1115	1115	1129	1120	1122
				1128	1104	1115	1125	1128	1127	1124	1127	1110	1122	1127	1122	1136	1122	1122	1108	1127	1125	1118	1111	1122	1127	1114	1129	1107	1131	1114	1111	1129	1113
				1122	1124	1122	1124	1121	1120	1122	1132	1117	1125	1118	1122	1113	1124	1122	1120	1115	1120	1110	1101	1127	1129	1132	1114	1124	1124	1113	1114	1121	1121
				1120	1125	1108	1110	1121	1128	1120	1115	1115	1110	1122	1118	1117	1139	1120	1117	1108	1127	1121	1122	1110	1106	1128	1128	1131	1107	1134	1113	1117	1110
				1115	1122	1129	1125	1121	1122	1111	1118	1128	1117	1122	1115	1117	1115	1127	1122	1121	1114	1121	1115	1104	1127	1120	1134	1117	1127	1125	1115	1118	1117
				1107	1122	1128	1108	1118	1120	1124	1120	1121	1113	1114	1124	1125	1118	1138	1113	1113	1108	1125	1127	1125	1113	1132	1107	1131	1135	1113	1127	1111	1118
				1115	1108	1121	1129	1124	1124	1121	1131	1117	1127	1122	1118	1115	1120	1111	1114	1117	1124	1120	1117	1113	1104	1117	1117	1136	1117	1125	1122	1120	1122
				1114	1114	1124	1131	1110	1111	1127	1121	1122	1120	1114	1113	1124	1121	1115	1117	1120	1111	1110	1127	1127	1125	1113	1131	1106	1136	1128	1111	1128	1115
				1122	1114	1107	1118	1120	1129	1127	1125	1117	1124	1131	1129	1127	1114	1117	1107	1110	1113	1115	1122	1122	1113	1110	1125	1122	1132	1115	1120	1134	1120
				1107	1111	1115	1124	1124	1118	1113	1117	1128	1120	1114	1125	1110	1120	1120	1117	1113	1118	1121	1128	1124	1125	1124	1113	1146	1107	1135	1129	1114	1129
				1124	1122	1115	1108	1120	1115	1117	1129	1120	1115	1127	1134	1131	1128	1113	1131	1101	1104	1114	1120	1127	1120	1114	1122	1122	1120	1129	1118	1120	1110
				1143	1118	1124	1121	1124	1117	1115	1114	1104	1128	1127	1115	1132	1114	1125	1122	1111	1124	1115	1118	1132	1125	1108	1110	1122	1145	1113	1128	1121	1110
				1124	1117	1111	1115	1129	1115	1108	1127	1120	1117	1113	1138	1136	1128	1125	1134	1132	1121	1104	1108	1110	1134	1117	1124	1121	1120	1113	1131	1120	1121
				1124	1128	1122	1131	1128	1134	1106	1128	1124	1107	1129	1120	1108	1127	1127	1110	1118	1118	1120	1124	1127	1127	1115	1129	1110	1124	1139	1125	1115	1108
				1138	1120	1114	1118	1131	1120	1111	1103	1117	1118	1113	1118	1129	1120	1125	1111	1124	1120	1128	1118	1100	1114	1118	1122	1115	1115	1117	1114	1128	1120
				1129	1124	1125	1125	1127	1124	1139	1115	1127	1121	1108	1132	1120	1114	1117	1107	1125	1121	1114	1124	1113	1131	1129	1111	1138	1108	1131	1143	1124	1129
				3840 3840 3840>;

			PS_Config_Lmt_FW_Rawdata_N = <
				475	481	482	476	481	480	484	479	482	480	482	478	477	481	477	476	477	480	479	477	486	484	475	486	478	480	478	475	480	479
				477	480	484	478	493	482	477	477	481	473	476	479	485	480	485	481	480	476	484	482	475	486	474	481	482	487	478	485	478	478
				479	484	483	478	479	481	484	479	481	480	475	476	480	484	480	483	480	487	487	482	486	473	478	475	475	473	475	484	482	483
				480	480	481	475	484	477	474	478	481	480	477	480	482	487	481	480	480	479	481	487	481	474	477	478	478	486	484	478	483	481
				480	479	483	481	482	482	483	480	480	476	478	478	476	478	475	475	483	480	483	484	480	481	483	479	478	476	476	479	477	478
				477	479	476	484	477	481	472	481	484	482	483	481	484	482	472	481	481	480	477	487	487	480	484	480	477	477	487	478	481	474
				484	480	478	486	481	484	477	473	469	478	480	481	481	477	476	481	476	484	481	481	482	478	477	480	483	486	479	475	480	479
				485	475	479	480	483	477	480	480	487	486	483	480	483	482	477	477	483	480	480	477	490	480	478	481	480	483	480	483	474	484
				477	481	483	478	486	484	484	480	481	469	478	481	483	483	482	477	482	477	484	479	483	478	478	481	482	482	487	483	481	486
				486	484	474	481	480	482	478	481	475	480	487	480	484	486	484	483	477	483	480	478	474	487	473	484	480	482	484	480	476	478
				478	484	483	480	479	486	480	480	480	480	472	483	484	485	486	479	478	487	477	485	480	479	477	480	485	480	480	486	489	488
				479	483	483	478	480	480	486	487	483	478	483	486	481	483	486	477	483	477	480	481	478	478	475	479	483	478	481	481	481	476
				479	477	485	484	479	478	482	478	477	482	480	475	477	483	484	480	481	476	486	477	486	478	481	479	478	484	481	480	478	482
				481	485	484	481	475	480	478	481	479	487	481	483	481	480	483	483	477	480	478	481	482	480	480	477	477	485	477	481	476	484
				483	480	476	484	486	478	478	481	486	480	483	481	476	479	482	477	481	478	480	486	477	486	480	477	478	478	481	481	477	475
				483	481	484	486	480	474	481	484	479	481	489	482	481	475	478	478	481	475	480	478	484	482	475	477	480	478	483	474	480	476
				481	484	477	478	486	485	478	475	481	484	478	483	482	479	478	478	479	477	479	479	484	477	481	479	478	481	484	483	481	478
				482	484	481	481	484	481	477	482	479	480	480	481	484	474	473	480	479	484	475	479	474	484	479	485	479	480	481	478	477	478
				480	481	484	475	480	487	478	479	479	481	484	478	481	482	480	484	480	478	476	479	479	484	479	481	483	480	483	483	483	478
				480	484	482	480	482	486	485	484	475	480	480	478	486	484	474	481	475	478	486	475	482	476	484	481	485	481	482	478	478	479
				477	478	481	483	476	480	486	474	481	478	481	482	478	483	482	478	483	481	478	477	478	472	484	477	484	486	481	483	486	477
				475	480	482	483	482	483	479	478	478	475	480	480	478	484	483	480	482	477	480	484	477	480	475	479	484	480	483	484	480	475
				481	478	479	482	481	479	481	485	478	483	481	481	477	478	480	481	479	483	482	480	475	481	479	483	480	482	485	480	485	479
				483	475	483	481	481	483	480	478	480	480	478	478	481	478	482	480	482	484	478	481	481	480	484	483	471	486	475	484	486	482
				480	481	478	479	481	482	477	483	478	480	484	483	476	475	478	481	480	479	483	481	481	478	476	479	478	480	483	486	480	483
				481	482	475	481	481	481	480	480	488	479	480	479	479	483	478	483	484	483	483	474	481	477	477	479	486	475	481	472	484	484
				480	486	481	477	479	481	481	484	478	480	480	486	483	477	474	475	483	480	480	481	480	477	481	481	481	479	482	483	484	483
				477	480	481	478	483	482	484	477	479	488	481	478	477	477	479	481	480	482	484	483	474	483	478	476	480	487	474	478	473	483
				484	481	483	481	481	479	481	477	477	476	480	482	484	485	477	475	474	481	483	481	483	482	483	479	478	483	478	481	484	480
				475	476	479	481	477	481	485	474	483	478	489	481	480	480	476	480	480	477	483	483	483	477	482	486	478	478	488	474	483	474
				482	481	481	475	481	474	481	486	476	476	477	481	481	483	484	478	477	474	482	480	483	480	482	483	476	479	481	475	480	481
				476	477	481	481	483	479	480	476	481	483	479	487	481	481	479	481	482	479	475	480	482	479	478	475	483	478	477	485	475	478
				484	481	481	477	475	481	475	481	481	477	479	477	481	481	483	475	480	475	472	483	480	481	482	482	481	478	478	484	480	481
				483	473	478	482	483	483	481	483	475	481	483	481	487	481	481	475	483	482	479	476	481	483	477	484	474	484	477	476	484	477
				481	481	481	481	480	480	481	485	478	482	479	481	477	481	481	480	478	480	475	472	483	484	485	477	481	481	477	477	480	480
				480	482	475	475	480	483	480	478	478	475	481	479	478	488	480	478	475	483	480	481	475	474	483	483	484	474	486	477	478	475
				478	481	484	482	480	481	476	479	483	478	481	478	478	478	483	481	480	477	480	478	473	483	480	486	478	483	482	478	479	478
				474	481	483	475	479	480	481	480	480	477	477	481	482	479	487	477	477	475	482	483	482	477	485	474	484	486	477	483	476	479
				478	475	480	484	481	481	480	484	478	483	481	479	478	480	476	477	478	481	480	478	477	473	478	478	487	478	482	481	480	481
				477	477	481	484	475	476	483	480	481	480	477	477	481	480	478	478	480	476	475	483	483	482	477	484	474	487	483	476	483	478
				481	477	474	479	480	484	483	482	478	481	484	484	483	477	478	474	475	477	478	481	481	477	475	482	481	485	478	480	486	480
				474	476	478	481	481	479	477	478	483	480	477	482	475	480	480	478	477	479	480	483	481	482	481	477	491	474	486	484	477	484
				481	481	478	475	480	478	478	484	480	478	483	486	484	483	477	484	472	473	477	480	483	480	477	481	481	480	484	479	480	475
				490	479	481	480	481	478	478	477	473	483	483	478	485	477	482	481	476	481	478	479	485	482	475	475	481	490	477	483	480	475
				481	478	476	478	484	478	475	483	480	478	477	487	487	483	482	486	485	480	473	475	475	486	478	481	480	480	477	484	480	480
				481	483	481	484	483	486	474	483	481	474	484	480	475	483	483	475	479	479	480	481	483	483	478	484	475	481	488	482	478	475
				487	480	477	479	484	480	476	472	478	479	477	479	484	480	482	476	481	480	483	479	471	477	479	481	478	478	478	477	483	480
				484	481	482	482	483	481	488	478	483	480	475	485	480	477	478	474	482	480	477	481	477	484	484	476	487	475	484	490	481	484
				240 240 240>;

			PS_Config_Lmt_FW_CC_P = <
				67	60	64	64	67	66	66	66	66	66	64	64	66	66	67	66	59	63	64	66	64	64	66	64	64	64	64	64	64	67
				64	60	63	66	64	64	66	64	63	64	64	64	64	64	63	63	60	63	64	64	63	64	64	63	63	63	63	63	64	63
				64	64	59	64	64	66	66	66	64	66	64	64	64	64	64	64	64	59	63	63	64	64	64	63	64	63	64	64	63	63
				64	64	60	64	66	64	64	66	64	64	64	64	64	64	64	64	63	59	63	64	64	63	64	63	63	63	63	63	64	64
				66	64	66	60	64	64	66	66	64	64	66	64	64	64	66	64	64	64	59	63	63	64	64	63	63	64	64	64	64	64
				64	64	64	62	64	66	66	64	64	64	64	64	64	64	66	63	64	63	60	63	64	64	63	63	64	63	63	63	63	64
				64	66	64	66	60	64	64	67	64	64	64	66	66	66	66	64	64	64	64	59	63	63	66	64	64	64	64	64	64	64
				66	64	64	64	62	64	66	66	66	64	66	64	64	64	64	64	63	64	63	60	63	64	64	64	63	64	63	63	64	64
				64	64	66	64	66	59	64	64	64	64	66	64	66	66	66	64	64	64	64	64	59	63	64	63	64	64	64	64	64	64
				66	66	64	64	64	60	64	66	64	66	64	66	64	64	64	64	64	63	64	63	60	63	64	63	64	64	64	63	63	64
				64	64	64	66	64	66	60	64	64	64	64	66	64	66	66	63	64	63	64	64	64	59	64	64	63	64	64	64	64	64
				66	66	66	64	64	64	62	64	64	66	66	64	66	64	64	64	64	64	63	64	63	60	63	63	64	64	64	64	63	64
				66	64	64	64	66	64	66	64	66	64	64	64	66	66	66	64	63	64	63	64	64	64	63	64	64	64	64	64	64	64
				64	64	66	66	64	64	64	66	64	64	64	66	64	66	64	64	64	64	64	63	64	63	64	63	63	64	64	64	64	63
				66	66	64	64	64	66	64	64	66	66	64	64	64	66	66	64	64	63	64	63	64	64	64	64	66	64	64	64	64	64
				66	64	64	66	66	64	66	66	66	64	64	66	66	66	66	64	64	64	64	64	63	64	64	66	64	64	64	64	64	64
				66	66	66	64	64	64	66	66	66	66	66	66	64	64	66	64	64	64	63	64	63	64	64	64	64	66	64	64	64	64
				64	66	64	66	66	66	64	64	66	66	64	66	66	66	66	64	64	64	64	64	64	63	63	64	66	64	64	64	64	64
				66	66	66	66	64	64	64	66	66	66	66	67	66	64	66	66	64	64	64	63	64	64	64	64	64	64	66	64	64	64
				66	64	66	64	66	66	66	64	66	66	67	66	66	66	66	64	64	64	64	64	64	64	64	64	64	66	64	64	64	64
				64	67	66	66	66	64	64	66	66	66	66	66	67	66	64	64	66	64	64	64	63	64	64	64	64	64	64	66	64	64
				66	66	64	66	64	66	66	64	66	66	66	67	66	66	66	64	64	64	64	64	64	64	63	64	64	64	66	64	64	64
				64	64	66	66	66	66	64	67	66	66	66	66	66	67	66	64	64	66	64	64	64	63	66	64	64	64	64	64	66	66
				66	66	66	64	66	64	66	66	66	66	66	66	67	66	66	66	66	64	64	64	64	64	63	64	64	64	66	66	64	64
				67	64	64	66	66	66	66	64	67	66	66	66	66	66	67	66	64	64	66	64	64	64	63	66	66	64	64	64	64	66
				66	66	66	66	64	66	64	66	66	66	66	66	66	67	66	64	64	66	64	64	64	64	66	64	64	64	64	66	66	64
				66	67	64	64	66	66	66	66	66	67	66	66	66	66	66	66	66	64	64	66	64	64	64	64	66	66	64	64	64	64
				66	66	66	66	66	64	66	66	67	66	66	66	66	66	67	66	64	64	66	64	64	64	64	66	64	64	64	64	66	66
				67	66	67	64	64	66	66	66	66	66	67	66	66	66	66	66	66	66	64	64	66	66	64	64	64	66	66	64	64	64
				66	66	66	66	66	66	64	67	66	67	66	66	66	66	66	64	66	64	64	66	64	64	66	64	66	64	64	64	64	66
				66	67	66	67	64	64	67	66	66	66	66	67	66	66	66	64	66	66	66	64	64	66	64	64	64	64	66	66	64	66
				67	66	66	66	66	66	66	66	67	66	67	66	66	66	66	66	64	66	64	64	66	64	64	66	66	66	64	64	64	64
				66	66	67	66	67	64	64	66	66	66	66	66	67	66	66	66	64	66	66	66	64	64	64	64	64	64	64	66	66	66
				66	67	66	66	66	66	66	63	66	67	66	67	66	66	66	66	66	64	66	64	64	66	63	64	66	66	66	64	64	64
				66	66	66	67	66	67	66	62	66	66	66	66	66	67	66	64	66	64	66	66	66	64	60	64	64	64	64	64	66	66
				66	66	67	66	66	66	66	60	64	66	67	66	67	66	66	64	66	66	64	66	64	64	59	63	64	66	64	66	64	64
				67	66	66	66	67	66	67	64	62	66	66	66	66	66	67	66	64	66	64	66	66	66	64	60	64	66	64	64	64	66
				66	66	66	67	66	66	66	66	60	64	66	67	66	67	66	64	64	66	66	64	66	64	64	60	63	64	66	66	66	64
				67	67	66	66	66	67	66	67	66	62	66	66	66	66	66	66	66	64	66	64	66	66	66	66	60	64	66	64	64	64
				67	66	66	66	67	66	66	66	64	60	64	66	67	66	67	66	64	64	66	66	64	66	64	63	60	63	64	66	66	66
				67	66	67	66	66	66	67	66	66	66	62	66	66	66	66	66	66	66	64	64	64	66	66	64	66	60	64	64	64	64
				66	66	66	66	66	67	66	66	66	64	60	64	66	67	66	64	64	64	64	66	66	64	66	64	63	60	63	64	66	66
				67	67	66	67	66	66	66	67	66	66	66	62	66	66	66	66	66	66	66	64	64	64	66	64	64	66	60	64	64	66
				66	66	66	66	66	66	67	64	66	66	64	60	63	66	67	64	64	64	64	64	64	66	64	64	64	63	59	63	64	66
				66	67	67	66	66	66	66	66	66	66	64	66	62	66	66	64	66	66	64	66	64	64	64	64	64	64	66	60	64	66
				67	66	66	66	66	66	66	66	64	64	64	64	60	63	66	66	64	64	64	64	64	64	66	64	64	64	63	59	63	66
				64	64	67	66	66	66	66	66	64	64	66	64	66	60	66	64	64	66	66	64	66	64	64	64	64	64	64	66	60	64
				64	66	66	64	66	66	66	66	64	64	66	64	64	60	64	64	64	64	64	64	64	64	64	64	64	64	64	63	59	63
				314 314 314>;

			PS_Config_Lmt_FW_CC_N = <
				30	27	29	29	30	29	29	29	29	29	29	29	29	29	30	29	26	28	29	29	29	29	29	29	29	29	29	29	29	30
				29	27	28	29	29	29	29	29	28	29	29	29	29	29	28	28	27	28	29	29	28	29	29	28	28	28	28	28	29	28
				29	29	26	29	29	29	29	29	29	29	29	29	29	29	29	29	29	26	28	28	29	29	29	28	29	28	29	29	28	28
				29	29	27	29	29	29	29	29	29	29	29	29	29	29	29	29	28	26	28	29	29	28	29	28	28	28	28	28	29	29
				29	29	29	27	29	29	29	29	29	29	29	29	29	29	29	29	29	29	26	28	28	29	29	28	28	29	29	29	29	29
				29	29	29	27	29	29	29	29	29	29	29	29	29	29	29	28	29	28	27	28	29	29	28	28	29	28	28	28	28	29
				29	29	29	29	27	29	29	30	29	29	29	29	29	29	29	29	29	29	29	26	28	28	29	29	29	29	29	29	29	29
				29	29	29	29	27	29	29	29	29	29	29	29	29	29	29	29	28	29	28	27	28	29	29	29	28	29	28	28	29	29
				29	29	29	29	29	26	29	29	29	29	29	29	29	29	29	29	29	29	29	29	26	28	29	28	29	29	29	29	29	29
				29	29	29	29	29	27	29	29	29	29	29	29	29	29	29	29	29	28	29	28	27	28	29	28	29	29	29	28	28	29
				29	29	29	29	29	29	27	29	29	29	29	29	29	29	29	28	29	28	29	29	29	26	29	29	28	29	29	29	29	29
				29	29	29	29	29	29	27	29	29	29	29	29	29	29	29	29	29	29	28	29	28	27	28	28	29	29	29	29	28	29
				29	29	29	29	29	29	29	29	29	29	29	29	29	29	29	29	28	29	28	29	29	29	28	29	29	29	29	29	29	29
				29	29	29	29	29	29	29	29	29	29	29	29	29	29	29	29	29	29	29	28	29	28	29	28	28	29	29	29	29	28
				29	29	29	29	29	29	29	29	29	29	29	29	29	29	29	29	29	28	29	28	29	29	29	29	29	29	29	29	29	29
				29	29	29	29	29	29	29	29	29	29	29	29	29	29	29	29	29	29	29	29	28	29	29	29	29	29	29	29	29	29
				29	29	29	29	29	29	29	29	29	29	29	29	29	29	29	29	29	29	28	29	28	29	29	29	29	29	29	29	29	29
				29	29	29	29	29	29	29	29	29	29	29	29	29	29	29	29	29	29	29	29	29	28	28	29	29	29	29	29	29	29
				29	29	29	29	29	29	29	29	29	29	29	30	29	29	29	29	29	29	29	28	29	29	29	29	29	29	29	29	29	29
				29	29	29	29	29	29	29	29	29	29	30	29	29	29	29	29	29	29	29	29	29	29	29	29	29	29	29	29	29	29
				29	30	29	29	29	29	29	29	29	29	29	29	30	29	29	29	29	29	29	29	28	29	29	29	29	29	29	29	29	29
				29	29	29	29	29	29	29	29	29	29	29	30	29	29	29	29	29	29	29	29	29	29	28	29	29	29	29	29	29	29
				29	29	29	29	29	29	29	30	29	29	29	29	29	30	29	29	29	29	29	29	29	28	29	29	29	29	29	29	29	29
				29	29	29	29	29	29	29	29	29	29	29	29	30	29	29	29	29	29	29	29	29	29	28	29	29	29	29	29	29	29
				30	29	29	29	29	29	29	29	30	29	29	29	29	29	30	29	29	29	29	29	29	29	28	29	29	29	29	29	29	29
				29	29	29	29	29	29	29	29	29	29	29	29	29	30	29	29	29	29	29	29	29	29	29	29	29	29	29	29	29	29
				29	30	29	29	29	29	29	29	29	30	29	29	29	29	29	29	29	29	29	29	29	29	29	29	29	29	29	29	29	29
				29	29	29	29	29	29	29	29	30	29	29	29	29	29	30	29	29	29	29	29	29	29	29	29	29	29	29	29	29	29
				30	29	30	29	29	29	29	29	29	29	30	29	29	29	29	29	29	29	29	29	29	29	29	29	29	29	29	29	29	29
				29	29	29	29	29	29	29	30	29	30	29	29	29	29	29	29	29	29	29	29	29	29	29	29	29	29	29	29	29	29
				29	30	29	30	29	29	30	29	29	29	29	30	29	29	29	29	29	29	29	29	29	29	29	29	29	29	29	29	29	29
				30	29	29	29	29	29	29	29	30	29	30	29	29	29	29	29	29	29	29	29	29	29	29	29	29	29	29	29	29	29
				29	29	30	29	30	29	29	29	29	29	29	29	30	29	29	29	29	29	29	29	29	29	29	29	29	29	29	29	29	29
				29	30	29	29	29	29	29	28	29	30	29	30	29	29	29	29	29	29	29	29	29	29	28	29	29	29	29	29	29	29
				29	29	29	30	29	30	29	27	29	29	29	29	29	30	29	29	29	29	29	29	29	29	27	29	29	29	29	29	29	29
				29	29	30	29	29	29	29	27	29	29	30	29	30	29	29	29	29	29	29	29	29	29	26	28	29	29	29	29	29	29
				30	29	29	29	30	29	30	29	27	29	29	29	29	29	30	29	29	29	29	29	29	29	29	27	29	29	29	29	29	29
				29	29	29	30	29	29	29	29	27	29	29	30	29	30	29	29	29	29	29	29	29	29	29	27	28	29	29	29	29	29
				30	30	29	29	29	30	29	30	29	27	29	29	29	29	29	29	29	29	29	29	29	29	29	29	27	29	29	29	29	29
				30	29	29	29	30	29	29	29	29	27	29	29	30	29	30	29	29	29	29	29	29	29	29	28	27	28	29	29	29	29
				30	29	30	29	29	29	30	29	29	29	27	29	29	29	29	29	29	29	29	29	29	29	29	29	29	27	29	29	29	29
				29	29	29	29	29	30	29	29	29	29	27	29	29	30	29	29	29	29	29	29	29	29	29	29	28	27	28	29	29	29
				30	30	29	30	29	29	29	30	29	29	29	27	29	29	29	29	29	29	29	29	29	29	29	29	29	29	27	29	29	29
				29	29	29	29	29	29	30	29	29	29	29	27	28	29	30	29	29	29	29	29	29	29	29	29	29	28	26	28	29	29
				29	30	30	29	29	29	29	29	29	29	29	29	27	29	29	29	29	29	29	29	29	29	29	29	29	29	29	27	29	29
				30	29	29	29	29	29	29	29	29	29	29	29	27	28	29	29	29	29	29	29	29	29	29	29	29	29	28	26	28	29
				29	29	30	29	29	29	29	29	29	29	29	29	29	27	29	29	29	29	29	29	29	29	29	29	29	29	29	29	27	29
				29	29	29	29	29	29	29	29	29	29	29	29	29	27	29	29	29	29	29	29	29	29	29	29	29	29	29	28	26	28
				0 0 0>;

			PS_Config_Lmt_FW_Diff_P = <
				50	50	50	50	50	50	50	50	50	50	50	50	50	50	50	50	50	50	50	50	50	50	50	50	50	50	50	50	50	50
				50	50	50	50	50	50	50	50	50	50	50	50	50	50	50	50	50	50	50	50	50	50	50	50	50	50	50	50	50	50
				50	50	50	50	50	50	50	50	50	50	50	50	50	50	50	50	50	50	50	50	50	50	50	50	50	50	50	50	50	50
				50	50	50	50	50	50	50	50	50	50	50	50	50	50	50	50	50	50	50	50	50	50	50	50	50	50	50	50	50	50
				50	50	50	50	50	50	50	50	50	50	50	50	50	50	50	50	50	50	50	50	50	50	50	50	50	50	50	50	50	50
				50	50	50	50	50	50	50	50	50	50	50	50	50	50	50	50	50	50	50	50	50	50	50	50	50	50	50	50	50	50
				50	50	50	50	50	50	50	50	50	50	50	50	50	50	50	50	50	50	50	50	50	50	50	50	50	50	50	50	50	50
				50	50	50	50	50	50	50	50	50	50	50	50	50	50	50	50	50	50	50	50	50	50	50	50	50	50	50	50	50	50
				50	50	50	50	50	50	50	50	50	50	50	50	50	50	50	50	50	50	50	50	50	50	50	50	50	50	50	50	50	50
				50	50	50	50	50	50	50	50	50	50	50	50	50	50	50	50	50	50	50	50	50	50	50	50	50	50	50	50	50	50
				50	50	50	50	50	50	50	50	50	50	50	50	50	50	50	50	50	50	50	50	50	50	50	50	50	50	50	50	50	50
				50	50	50	50	50	50	50	50	50	50	50	50	50	50	50	50	50	50	50	50	50	50	50	50	50	50	50	50	50	50
				50	50	50	50	50	50	50	50	50	50	50	50	50	50	50	50	50	50	50	50	50	50	50	50	50	50	50	50	50	50
				50	50	50	50	50	50	50	50	50	50	50	50	50	50	50	50	50	50	50	50	50	50	50	50	50	50	50	50	50	50
				50	50	50	50	50	50	50	50	50	50	50	50	50	50	50	50	50	50	50	50	50	50	50	50	50	50	50	50	50	50
				50	50	50	50	50	50	50	50	50	50	50	50	50	50	50	50	50	50	50	50	50	50	50	50	50	50	50	50	50	50
				50	50	50	50	50	50	50	50	50	50	50	50	50	50	50	50	50	50	50	50	50	50	50	50	50	50	50	50	50	50
				50	50	50	50	50	50	50	50	50	50	50	50	50	50	50	50	50	50	50	50	50	50	50	50	50	50	50	50	50	50
				50	50	50	50	50	50	50	50	50	50	50	50	50	50	50	50	50	50	50	50	50	50	50	50	50	50	50	50	50	50
				50	50	50	50	50	50	50	50	50	50	50	50	50	50	50	50	50	50	50	50	50	50	50	50	50	50	50	50	50	50
				50	50	50	50	50	50	50	50	50	50	50	50	50	50	50	50	50	50	50	50	50	50	50	50	50	50	50	50	50	50
				50	50	50	50	50	50	50	50	50	50	50	50	50	50	50	50	50	50	50	50	50	50	50	50	50	50	50	50	50	50
				50	50	50	50	50	50	50	50	50	50	50	50	50	50	50	50	50	50	50	50	50	50	50	50	50	50	50	50	50	50
				50	50	50	50	50	50	50	50	50	50	50	50	50	50	50	50	50	50	50	50	50	50	50	50	50	50	50	50	50	50
				50	50	50	50	50	50	50	50	50	50	50	50	50	50	50	50	50	50	50	50	50	50	50	50	50	50	50	50	50	50
				50	50	50	50	50	50	50	50	50	50	50	50	50	50	50	50	50	50	50	50	50	50	50	50	50	50	50	50	50	50
				50	50	50	50	50	50	50	50	50	50	50	50	50	50	50	50	50	50	50	50	50	50	50	50	50	50	50	50	50	50
				50	50	50	50	50	50	50	50	50	50	50	50	50	50	50	50	50	50	50	50	50	50	50	50	50	50	50	50	50	50
				50	50	50	50	50	50	50	50	50	50	50	50	50	50	50	50	50	50	50	50	50	50	50	50	50	50	50	50	50	50
				50	50	50	50	50	50	50	50	50	50	50	50	50	50	50	50	50	50	50	50	50	50	50	50	50	50	50	50	50	50
				50	50	50	50	50	50	50	50	50	50	50	50	50	50	50	50	50	50	50	50	50	50	50	50	50	50	50	50	50	50
				50	50	50	50	50	50	50	50	50	50	50	50	50	50	50	50	50	50	50	50	50	50	50	50	50	50	50	50	50	50
				50	50	50	50	50	50	50	50	50	50	50	50	50	50	50	50	50	50	50	50	50	50	50	50	50	50	50	50	50	50
				50	50	50	50	50	50	50	50	50	50	50	50	50	50	50	50	50	50	50	50	50	50	50	50	50	50	50	50	50	50
				50	50	50	50	50	50	50	50	50	50	50	50	50	50	50	50	50	50	50	50	50	50	50	50	50	50	50	50	50	50
				50	50	50	50	50	50	50	50	50	50	50	50	50	50	50	50	50	50	50	50	50	50	50	50	50	50	50	50	50	50
				50	50	50	50	50	50	50	50	50	50	50	50	50	50	50	50	50	50	50	50	50	50	50	50	50	50	50	50	50	50
				50	50	50	50	50	50	50	50	50	50	50	50	50	50	50	50	50	50	50	50	50	50	50	50	50	50	50	50	50	50
				50	50	50	50	50	50	50	50	50	50	50	50	50	50	50	50	50	50	50	50	50	50	50	50	50	50	50	50	50	50
				50	50	50	50	50	50	50	50	50	50	50	50	50	50	50	50	50	50	50	50	50	50	50	50	50	50	50	50	50	50
				50	50	50	50	50	50	50	50	50	50	50	50	50	50	50	50	50	50	50	50	50	50	50	50	50	50	50	50	50	50
				50	50	50	50	50	50	50	50	50	50	50	50	50	50	50	50	50	50	50	50	50	50	50	50	50	50	50	50	50	50
				50	50	50	50	50	50	50	50	50	50	50	50	50	50	50	50	50	50	50	50	50	50	50	50	50	50	50	50	50	50
				50	50	50	50	50	50	50	50	50	50	50	50	50	50	50	50	50	50	50	50	50	50	50	50	50	50	50	50	50	50
				50	50	50	50	50	50	50	50	50	50	50	50	50	50	50	50	50	50	50	50	50	50	50	50	50	50	50	50	50	50
				50	50	50	50	50	50	50	50	50	50	50	50	50	50	50	50	50	50	50	50	50	50	50	50	50	50	50	50	50	50
				50	50	50	50	50	50	50	50	50	50	50	50	50	50	50	50	50	50	50	50	50	50	50	50	50	50	50	50	50	50
				50	50	50	50	50	50	50	50	50	50	50	50	50	50	50	50	50	50	50	50	50	50	50	50	50	50	50	50	50	50
				75 75 75>;

			PS_Config_Lmt_FW_Diff_N = <
				(-50)	(-50)	(-50)	(-50)	(-50)	(-50)	(-50)	(-50)	(-50)	(-50)	(-50)	(-50)	(-50)	(-50)	(-50)	(-50)	(-50)	(-50)	(-50)	(-50)	(-50)	(-50)	(-50)	(-50)	(-50)	(-50)	(-50)	(-50)	(-50)	(-50)
				(-50)	(-50)	(-50)	(-50)	(-50)	(-50)	(-50)	(-50)	(-50)	(-50)	(-50)	(-50)	(-50)	(-50)	(-50)	(-50)	(-50)	(-50)	(-50)	(-50)	(-50)	(-50)	(-50)	(-50)	(-50)	(-50)	(-50)	(-50)	(-50)	(-50)
				(-50)	(-50)	(-50)	(-50)	(-50)	(-50)	(-50)	(-50)	(-50)	(-50)	(-50)	(-50)	(-50)	(-50)	(-50)	(-50)	(-50)	(-50)	(-50)	(-50)	(-50)	(-50)	(-50)	(-50)	(-50)	(-50)	(-50)	(-50)	(-50)	(-50)
				(-50)	(-50)	(-50)	(-50)	(-50)	(-50)	(-50)	(-50)	(-50)	(-50)	(-50)	(-50)	(-50)	(-50)	(-50)	(-50)	(-50)	(-50)	(-50)	(-50)	(-50)	(-50)	(-50)	(-50)	(-50)	(-50)	(-50)	(-50)	(-50)	(-50)
				(-50)	(-50)	(-50)	(-50)	(-50)	(-50)	(-50)	(-50)	(-50)	(-50)	(-50)	(-50)	(-50)	(-50)	(-50)	(-50)	(-50)	(-50)	(-50)	(-50)	(-50)	(-50)	(-50)	(-50)	(-50)	(-50)	(-50)	(-50)	(-50)	(-50)
				(-50)	(-50)	(-50)	(-50)	(-50)	(-50)	(-50)	(-50)	(-50)	(-50)	(-50)	(-50)	(-50)	(-50)	(-50)	(-50)	(-50)	(-50)	(-50)	(-50)	(-50)	(-50)	(-50)	(-50)	(-50)	(-50)	(-50)	(-50)	(-50)	(-50)
				(-50)	(-50)	(-50)	(-50)	(-50)	(-50)	(-50)	(-50)	(-50)	(-50)	(-50)	(-50)	(-50)	(-50)	(-50)	(-50)	(-50)	(-50)	(-50)	(-50)	(-50)	(-50)	(-50)	(-50)	(-50)	(-50)	(-50)	(-50)	(-50)	(-50)
				(-50)	(-50)	(-50)	(-50)	(-50)	(-50)	(-50)	(-50)	(-50)	(-50)	(-50)	(-50)	(-50)	(-50)	(-50)	(-50)	(-50)	(-50)	(-50)	(-50)	(-50)	(-50)	(-50)	(-50)	(-50)	(-50)	(-50)	(-50)	(-50)	(-50)
				(-50)	(-50)	(-50)	(-50)	(-50)	(-50)	(-50)	(-50)	(-50)	(-50)	(-50)	(-50)	(-50)	(-50)	(-50)	(-50)	(-50)	(-50)	(-50)	(-50)	(-50)	(-50)	(-50)	(-50)	(-50)	(-50)	(-50)	(-50)	(-50)	(-50)
				(-50)	(-50)	(-50)	(-50)	(-50)	(-50)	(-50)	(-50)	(-50)	(-50)	(-50)	(-50)	(-50)	(-50)	(-50)	(-50)	(-50)	(-50)	(-50)	(-50)	(-50)	(-50)	(-50)	(-50)	(-50)	(-50)	(-50)	(-50)	(-50)	(-50)
				(-50)	(-50)	(-50)	(-50)	(-50)	(-50)	(-50)	(-50)	(-50)	(-50)	(-50)	(-50)	(-50)	(-50)	(-50)	(-50)	(-50)	(-50)	(-50)	(-50)	(-50)	(-50)	(-50)	(-50)	(-50)	(-50)	(-50)	(-50)	(-50)	(-50)
				(-50)	(-50)	(-50)	(-50)	(-50)	(-50)	(-50)	(-50)	(-50)	(-50)	(-50)	(-50)	(-50)	(-50)	(-50)	(-50)	(-50)	(-50)	(-50)	(-50)	(-50)	(-50)	(-50)	(-50)	(-50)	(-50)	(-50)	(-50)	(-50)	(-50)
				(-50)	(-50)	(-50)	(-50)	(-50)	(-50)	(-50)	(-50)	(-50)	(-50)	(-50)	(-50)	(-50)	(-50)	(-50)	(-50)	(-50)	(-50)	(-50)	(-50)	(-50)	(-50)	(-50)	(-50)	(-50)	(-50)	(-50)	(-50)	(-50)	(-50)
				(-50)	(-50)	(-50)	(-50)	(-50)	(-50)	(-50)	(-50)	(-50)	(-50)	(-50)	(-50)	(-50)	(-50)	(-50)	(-50)	(-50)	(-50)	(-50)	(-50)	(-50)	(-50)	(-50)	(-50)	(-50)	(-50)	(-50)	(-50)	(-50)	(-50)
				(-50)	(-50)	(-50)	(-50)	(-50)	(-50)	(-50)	(-50)	(-50)	(-50)	(-50)	(-50)	(-50)	(-50)	(-50)	(-50)	(-50)	(-50)	(-50)	(-50)	(-50)	(-50)	(-50)	(-50)	(-50)	(-50)	(-50)	(-50)	(-50)	(-50)
				(-50)	(-50)	(-50)	(-50)	(-50)	(-50)	(-50)	(-50)	(-50)	(-50)	(-50)	(-50)	(-50)	(-50)	(-50)	(-50)	(-50)	(-50)	(-50)	(-50)	(-50)	(-50)	(-50)	(-50)	(-50)	(-50)	(-50)	(-50)	(-50)	(-50)
				(-50)	(-50)	(-50)	(-50)	(-50)	(-50)	(-50)	(-50)	(-50)	(-50)	(-50)	(-50)	(-50)	(-50)	(-50)	(-50)	(-50)	(-50)	(-50)	(-50)	(-50)	(-50)	(-50)	(-50)	(-50)	(-50)	(-50)	(-50)	(-50)	(-50)
				(-50)	(-50)	(-50)	(-50)	(-50)	(-50)	(-50)	(-50)	(-50)	(-50)	(-50)	(-50)	(-50)	(-50)	(-50)	(-50)	(-50)	(-50)	(-50)	(-50)	(-50)	(-50)	(-50)	(-50)	(-50)	(-50)	(-50)	(-50)	(-50)	(-50)
				(-50)	(-50)	(-50)	(-50)	(-50)	(-50)	(-50)	(-50)	(-50)	(-50)	(-50)	(-50)	(-50)	(-50)	(-50)	(-50)	(-50)	(-50)	(-50)	(-50)	(-50)	(-50)	(-50)	(-50)	(-50)	(-50)	(-50)	(-50)	(-50)	(-50)
				(-50)	(-50)	(-50)	(-50)	(-50)	(-50)	(-50)	(-50)	(-50)	(-50)	(-50)	(-50)	(-50)	(-50)	(-50)	(-50)	(-50)	(-50)	(-50)	(-50)	(-50)	(-50)	(-50)	(-50)	(-50)	(-50)	(-50)	(-50)	(-50)	(-50)
				(-50)	(-50)	(-50)	(-50)	(-50)	(-50)	(-50)	(-50)	(-50)	(-50)	(-50)	(-50)	(-50)	(-50)	(-50)	(-50)	(-50)	(-50)	(-50)	(-50)	(-50)	(-50)	(-50)	(-50)	(-50)	(-50)	(-50)	(-50)	(-50)	(-50)
				(-50)	(-50)	(-50)	(-50)	(-50)	(-50)	(-50)	(-50)	(-50)	(-50)	(-50)	(-50)	(-50)	(-50)	(-50)	(-50)	(-50)	(-50)	(-50)	(-50)	(-50)	(-50)	(-50)	(-50)	(-50)	(-50)	(-50)	(-50)	(-50)	(-50)
				(-50)	(-50)	(-50)	(-50)	(-50)	(-50)	(-50)	(-50)	(-50)	(-50)	(-50)	(-50)	(-50)	(-50)	(-50)	(-50)	(-50)	(-50)	(-50)	(-50)	(-50)	(-50)	(-50)	(-50)	(-50)	(-50)	(-50)	(-50)	(-50)	(-50)
				(-50)	(-50)	(-50)	(-50)	(-50)	(-50)	(-50)	(-50)	(-50)	(-50)	(-50)	(-50)	(-50)	(-50)	(-50)	(-50)	(-50)	(-50)	(-50)	(-50)	(-50)	(-50)	(-50)	(-50)	(-50)	(-50)	(-50)	(-50)	(-50)	(-50)
				(-50)	(-50)	(-50)	(-50)	(-50)	(-50)	(-50)	(-50)	(-50)	(-50)	(-50)	(-50)	(-50)	(-50)	(-50)	(-50)	(-50)	(-50)	(-50)	(-50)	(-50)	(-50)	(-50)	(-50)	(-50)	(-50)	(-50)	(-50)	(-50)	(-50)
				(-50)	(-50)	(-50)	(-50)	(-50)	(-50)	(-50)	(-50)	(-50)	(-50)	(-50)	(-50)	(-50)	(-50)	(-50)	(-50)	(-50)	(-50)	(-50)	(-50)	(-50)	(-50)	(-50)	(-50)	(-50)	(-50)	(-50)	(-50)	(-50)	(-50)
				(-50)	(-50)	(-50)	(-50)	(-50)	(-50)	(-50)	(-50)	(-50)	(-50)	(-50)	(-50)	(-50)	(-50)	(-50)	(-50)	(-50)	(-50)	(-50)	(-50)	(-50)	(-50)	(-50)	(-50)	(-50)	(-50)	(-50)	(-50)	(-50)	(-50)
				(-50)	(-50)	(-50)	(-50)	(-50)	(-50)	(-50)	(-50)	(-50)	(-50)	(-50)	(-50)	(-50)	(-50)	(-50)	(-50)	(-50)	(-50)	(-50)	(-50)	(-50)	(-50)	(-50)	(-50)	(-50)	(-50)	(-50)	(-50)	(-50)	(-50)
				(-50)	(-50)	(-50)	(-50)	(-50)	(-50)	(-50)	(-50)	(-50)	(-50)	(-50)	(-50)	(-50)	(-50)	(-50)	(-50)	(-50)	(-50)	(-50)	(-50)	(-50)	(-50)	(-50)	(-50)	(-50)	(-50)	(-50)	(-50)	(-50)	(-50)
				(-50)	(-50)	(-50)	(-50)	(-50)	(-50)	(-50)	(-50)	(-50)	(-50)	(-50)	(-50)	(-50)	(-50)	(-50)	(-50)	(-50)	(-50)	(-50)	(-50)	(-50)	(-50)	(-50)	(-50)	(-50)	(-50)	(-50)	(-50)	(-50)	(-50)
				(-50)	(-50)	(-50)	(-50)	(-50)	(-50)	(-50)	(-50)	(-50)	(-50)	(-50)	(-50)	(-50)	(-50)	(-50)	(-50)	(-50)	(-50)	(-50)	(-50)	(-50)	(-50)	(-50)	(-50)	(-50)	(-50)	(-50)	(-50)	(-50)	(-50)
				(-50)	(-50)	(-50)	(-50)	(-50)	(-50)	(-50)	(-50)	(-50)	(-50)	(-50)	(-50)	(-50)	(-50)	(-50)	(-50)	(-50)	(-50)	(-50)	(-50)	(-50)	(-50)	(-50)	(-50)	(-50)	(-50)	(-50)	(-50)	(-50)	(-50)
				(-50)	(-50)	(-50)	(-50)	(-50)	(-50)	(-50)	(-50)	(-50)	(-50)	(-50)	(-50)	(-50)	(-50)	(-50)	(-50)	(-50)	(-50)	(-50)	(-50)	(-50)	(-50)	(-50)	(-50)	(-50)	(-50)	(-50)	(-50)	(-50)	(-50)
				(-50)	(-50)	(-50)	(-50)	(-50)	(-50)	(-50)	(-50)	(-50)	(-50)	(-50)	(-50)	(-50)	(-50)	(-50)	(-50)	(-50)	(-50)	(-50)	(-50)	(-50)	(-50)	(-50)	(-50)	(-50)	(-50)	(-50)	(-50)	(-50)	(-50)
				(-50)	(-50)	(-50)	(-50)	(-50)	(-50)	(-50)	(-50)	(-50)	(-50)	(-50)	(-50)	(-50)	(-50)	(-50)	(-50)	(-50)	(-50)	(-50)	(-50)	(-50)	(-50)	(-50)	(-50)	(-50)	(-50)	(-50)	(-50)	(-50)	(-50)
				(-50)	(-50)	(-50)	(-50)	(-50)	(-50)	(-50)	(-50)	(-50)	(-50)	(-50)	(-50)	(-50)	(-50)	(-50)	(-50)	(-50)	(-50)	(-50)	(-50)	(-50)	(-50)	(-50)	(-50)	(-50)	(-50)	(-50)	(-50)	(-50)	(-50)
				(-50)	(-50)	(-50)	(-50)	(-50)	(-50)	(-50)	(-50)	(-50)	(-50)	(-50)	(-50)	(-50)	(-50)	(-50)	(-50)	(-50)	(-50)	(-50)	(-50)	(-50)	(-50)	(-50)	(-50)	(-50)	(-50)	(-50)	(-50)	(-50)	(-50)
				(-50)	(-50)	(-50)	(-50)	(-50)	(-50)	(-50)	(-50)	(-50)	(-50)	(-50)	(-50)	(-50)	(-50)	(-50)	(-50)	(-50)	(-50)	(-50)	(-50)	(-50)	(-50)	(-50)	(-50)	(-50)	(-50)	(-50)	(-50)	(-50)	(-50)
				(-50)	(-50)	(-50)	(-50)	(-50)	(-50)	(-50)	(-50)	(-50)	(-50)	(-50)	(-50)	(-50)	(-50)	(-50)	(-50)	(-50)	(-50)	(-50)	(-50)	(-50)	(-50)	(-50)	(-50)	(-50)	(-50)	(-50)	(-50)	(-50)	(-50)
				(-50)	(-50)	(-50)	(-50)	(-50)	(-50)	(-50)	(-50)	(-50)	(-50)	(-50)	(-50)	(-50)	(-50)	(-50)	(-50)	(-50)	(-50)	(-50)	(-50)	(-50)	(-50)	(-50)	(-50)	(-50)	(-50)	(-50)	(-50)	(-50)	(-50)
				(-50)	(-50)	(-50)	(-50)	(-50)	(-50)	(-50)	(-50)	(-50)	(-50)	(-50)	(-50)	(-50)	(-50)	(-50)	(-50)	(-50)	(-50)	(-50)	(-50)	(-50)	(-50)	(-50)	(-50)	(-50)	(-50)	(-50)	(-50)	(-50)	(-50)
				(-50)	(-50)	(-50)	(-50)	(-50)	(-50)	(-50)	(-50)	(-50)	(-50)	(-50)	(-50)	(-50)	(-50)	(-50)	(-50)	(-50)	(-50)	(-50)	(-50)	(-50)	(-50)	(-50)	(-50)	(-50)	(-50)	(-50)	(-50)	(-50)	(-50)
				(-50)	(-50)	(-50)	(-50)	(-50)	(-50)	(-50)	(-50)	(-50)	(-50)	(-50)	(-50)	(-50)	(-50)	(-50)	(-50)	(-50)	(-50)	(-50)	(-50)	(-50)	(-50)	(-50)	(-50)	(-50)	(-50)	(-50)	(-50)	(-50)	(-50)
				(-50)	(-50)	(-50)	(-50)	(-50)	(-50)	(-50)	(-50)	(-50)	(-50)	(-50)	(-50)	(-50)	(-50)	(-50)	(-50)	(-50)	(-50)	(-50)	(-50)	(-50)	(-50)	(-50)	(-50)	(-50)	(-50)	(-50)	(-50)	(-50)	(-50)
				(-50)	(-50)	(-50)	(-50)	(-50)	(-50)	(-50)	(-50)	(-50)	(-50)	(-50)	(-50)	(-50)	(-50)	(-50)	(-50)	(-50)	(-50)	(-50)	(-50)	(-50)	(-50)	(-50)	(-50)	(-50)	(-50)	(-50)	(-50)	(-50)	(-50)
				(-50)	(-50)	(-50)	(-50)	(-50)	(-50)	(-50)	(-50)	(-50)	(-50)	(-50)	(-50)	(-50)	(-50)	(-50)	(-50)	(-50)	(-50)	(-50)	(-50)	(-50)	(-50)	(-50)	(-50)	(-50)	(-50)	(-50)	(-50)	(-50)	(-50)
				(-50)	(-50)	(-50)	(-50)	(-50)	(-50)	(-50)	(-50)	(-50)	(-50)	(-50)	(-50)	(-50)	(-50)	(-50)	(-50)	(-50)	(-50)	(-50)	(-50)	(-50)	(-50)	(-50)	(-50)	(-50)	(-50)	(-50)	(-50)	(-50)	(-50)
				(-50)	(-50)	(-50)	(-50)	(-50)	(-50)	(-50)	(-50)	(-50)	(-50)	(-50)	(-50)	(-50)	(-50)	(-50)	(-50)	(-50)	(-50)	(-50)	(-50)	(-50)	(-50)	(-50)	(-50)	(-50)	(-50)	(-50)	(-50)	(-50)	(-50)
				(-75) (-75) (-75)>;

			PS_Config_Lmt_PenTipX_FW_Raw_P = <
				570 570 570 570 570 570 570 570 570 570 570 570 570 570 570 570 570 570 570 570 570 570 570 570 570 570 570 570 570 570 570 570
				570 570 570 570 570 570 570 570 570 570 570 570 570 570 570 570 570 570 570 570 570 570 570 570 570 570 570 570 570 570 570 570
				570 570 570 570 570 570 570 570 570 570 570 570 570 570 570 570 570 570 570 570 570 570 570 570 570 570 570 570 570 570 570 570
				570 570 570 570 570 570 570 570 570 570 570 570 570 570 570 570 570 570 570 570 570 570 570 570 570 570 570 570 570 570 570 570
				570 570 570 570 570 570 570 570 570 570 570 570 570 570 570 570 570 570 570 570 570 570 570 570 570 570 570 570 570 570 570 570
				570 570 570 570 570 570 570 570 570 570 570 570 570 570 570 570 570 570 570 570 570 570 570 570 570 570 570 570 570 570 570 570>;

			PS_Config_Lmt_PenTipX_FW_Raw_N = <
				(-570) (-570) (-570) (-570) (-570) (-570) (-570) (-570) (-570) (-570) (-570) (-570) (-570) (-570) (-570) (-570) (-570) (-570) (-570) (-570) (-570) (-570) (-570) (-570) (-570) (-570) (-570) (-570) (-570) (-570) (-570) (-570)
				(-570) (-570) (-570) (-570) (-570) (-570) (-570) (-570) (-570) (-570) (-570) (-570) (-570) (-570) (-570) (-570) (-570) (-570) (-570) (-570) (-570) (-570) (-570) (-570) (-570) (-570) (-570) (-570) (-570) (-570) (-570) (-570)
				(-570) (-570) (-570) (-570) (-570) (-570) (-570) (-570) (-570) (-570) (-570) (-570) (-570) (-570) (-570) (-570) (-570) (-570) (-570) (-570) (-570) (-570) (-570) (-570) (-570) (-570) (-570) (-570) (-570) (-570) (-570) (-570)
				(-570) (-570) (-570) (-570) (-570) (-570) (-570) (-570) (-570) (-570) (-570) (-570) (-570) (-570) (-570) (-570) (-570) (-570) (-570) (-570) (-570) (-570) (-570) (-570) (-570) (-570) (-570) (-570) (-570) (-570) (-570) (-570)
				(-570) (-570) (-570) (-570) (-570) (-570) (-570) (-570) (-570) (-570) (-570) (-570) (-570) (-570) (-570) (-570) (-570) (-570) (-570) (-570) (-570) (-570) (-570) (-570) (-570) (-570) (-570) (-570) (-570) (-570) (-570) (-570)
				(-570) (-570) (-570) (-570) (-570) (-570) (-570) (-570) (-570) (-570) (-570) (-570) (-570) (-570) (-570) (-570) (-570) (-570) (-570) (-570) (-570) (-570) (-570) (-570) (-570) (-570) (-570) (-570) (-570) (-570) (-570) (-570)>;

			PS_Config_Lmt_PenTipY_FW_Raw_P = <
				570 570 570 570
				570 570 570 570
				570 570 570 570
				570 570 570 570
				570 570 570 570
				570 570 570 570
				570 570 570 570
				570 570 570 570
				570 570 570 570
				570 570 570 570
				570 570 570 570
				570 570 570 570
				570 570 570 570
				570 570 570 570
				570 570 570 570
				570 570 570 570
				570 570 570 570
				570 570 570 570
				570 570 570 570
				570 570 570 570
				570 570 570 570
				570 570 570 570
				570 570 570 570
				570 570 570 570
				570 570 570 570
				570 570 570 570
				570 570 570 570
				570 570 570 570
				570 570 570 570
				570 570 570 570
				570 570 570 570
				570 570 570 570
				570 570 570 570
				570 570 570 570
				570 570 570 570
				570 570 570 570
				570 570 570 570
				570 570 570 570
				570 570 570 570
				570 570 570 570
				570 570 570 570
				570 570 570 570
				570 570 570 570
				570 570 570 570
				570 570 570 570
				570 570 570 570
				570 570 570 570
				570 570 570 570
				570 570 570 570
				570 570 570 570>;

			PS_Config_Lmt_PenTipY_FW_Raw_N = <
				(-570) (-570) (-570) (-570)
				(-570) (-570) (-570) (-570)
				(-570) (-570) (-570) (-570)
				(-570) (-570) (-570) (-570)
				(-570) (-570) (-570) (-570)
				(-570) (-570) (-570) (-570)
				(-570) (-570) (-570) (-570)
				(-570) (-570) (-570) (-570)
				(-570) (-570) (-570) (-570)
				(-570) (-570) (-570) (-570)
				(-570) (-570) (-570) (-570)
				(-570) (-570) (-570) (-570)
				(-570) (-570) (-570) (-570)
				(-570) (-570) (-570) (-570)
				(-570) (-570) (-570) (-570)
				(-570) (-570) (-570) (-570)
				(-570) (-570) (-570) (-570)
				(-570) (-570) (-570) (-570)
				(-570) (-570) (-570) (-570)
				(-570) (-570) (-570) (-570)
				(-570) (-570) (-570) (-570)
				(-570) (-570) (-570) (-570)
				(-570) (-570) (-570) (-570)
				(-570) (-570) (-570) (-570)
				(-570) (-570) (-570) (-570)
				(-570) (-570) (-570) (-570)
				(-570) (-570) (-570) (-570)
				(-570) (-570) (-570) (-570)
				(-570) (-570) (-570) (-570)
				(-570) (-570) (-570) (-570)
				(-570) (-570) (-570) (-570)
				(-570) (-570) (-570) (-570)
				(-570) (-570) (-570) (-570)
				(-570) (-570) (-570) (-570)
				(-570) (-570) (-570) (-570)
				(-570) (-570) (-570) (-570)
				(-570) (-570) (-570) (-570)
				(-570) (-570) (-570) (-570)
				(-570) (-570) (-570) (-570)
				(-570) (-570) (-570) (-570)
				(-570) (-570) (-570) (-570)
				(-570) (-570) (-570) (-570)
				(-570) (-570) (-570) (-570)
				(-570) (-570) (-570) (-570)
				(-570) (-570) (-570) (-570)
				(-570) (-570) (-570) (-570)
				(-570) (-570) (-570) (-570)
				(-570) (-570) (-570) (-570)
				(-570) (-570) (-570) (-570)
				(-570) (-570) (-570) (-570)>;

			PS_Config_Lmt_PenRingX_FW_Raw_P = <
				570 570 570 570 570 570 570 570 570 570 570 570 570 570 570 570 570 570 570 570 570 570 570 570 570 570 570 570 570 570 570 570
				570 570 570 570 570 570 570 570 570 570 570 570 570 570 570 570 570 570 570 570 570 570 570 570 570 570 570 570 570 570 570 570
				570 570 570 570 570 570 570 570 570 570 570 570 570 570 570 570 570 570 570 570 570 570 570 570 570 570 570 570 570 570 570 570
				570 570 570 570 570 570 570 570 570 570 570 570 570 570 570 570 570 570 570 570 570 570 570 570 570 570 570 570 570 570 570 570
				570 570 570 570 570 570 570 570 570 570 570 570 570 570 570 570 570 570 570 570 570 570 570 570 570 570 570 570 570 570 570 570
				570 570 570 570 570 570 570 570 570 570 570 570 570 570 570 570 570 570 570 570 570 570 570 570 570 570 570 570 570 570 570 570>;

			PS_Config_Lmt_PenRingX_FW_Raw_N = <
				(-570) (-570) (-570) (-570) (-570) (-570) (-570) (-570) (-570) (-570) (-570) (-570) (-570) (-570) (-570) (-570) (-570) (-570) (-570) (-570) (-570) (-570) (-570) (-570) (-570) (-570) (-570) (-570) (-570) (-570) (-570) (-570)
				(-570) (-570) (-570) (-570) (-570) (-570) (-570) (-570) (-570) (-570) (-570) (-570) (-570) (-570) (-570) (-570) (-570) (-570) (-570) (-570) (-570) (-570) (-570) (-570) (-570) (-570) (-570) (-570) (-570) (-570) (-570) (-570)
				(-570) (-570) (-570) (-570) (-570) (-570) (-570) (-570) (-570) (-570) (-570) (-570) (-570) (-570) (-570) (-570) (-570) (-570) (-570) (-570) (-570) (-570) (-570) (-570) (-570) (-570) (-570) (-570) (-570) (-570) (-570) (-570)
				(-570) (-570) (-570) (-570) (-570) (-570) (-570) (-570) (-570) (-570) (-570) (-570) (-570) (-570) (-570) (-570) (-570) (-570) (-570) (-570) (-570) (-570) (-570) (-570) (-570) (-570) (-570) (-570) (-570) (-570) (-570) (-570)
				(-570) (-570) (-570) (-570) (-570) (-570) (-570) (-570) (-570) (-570) (-570) (-570) (-570) (-570) (-570) (-570) (-570) (-570) (-570) (-570) (-570) (-570) (-570) (-570) (-570) (-570) (-570) (-570) (-570) (-570) (-570) (-570)
				(-570) (-570) (-570) (-570) (-570) (-570) (-570) (-570) (-570) (-570) (-570) (-570) (-570) (-570) (-570) (-570) (-570) (-570) (-570) (-570) (-570) (-570) (-570) (-570) (-570) (-570) (-570) (-570) (-570) (-570) (-570) (-570)>;

			PS_Config_Lmt_PenRingY_FW_Raw_P = <
				570 570 570 570
				570 570 570 570
				570 570 570 570
				570 570 570 570
				570 570 570 570
				570 570 570 570
				570 570 570 570
				570 570 570 570
				570 570 570 570
				570 570 570 570
				570 570 570 570
				570 570 570 570
				570 570 570 570
				570 570 570 570
				570 570 570 570
				570 570 570 570
				570 570 570 570
				570 570 570 570
				570 570 570 570
				570 570 570 570
				570 570 570 570
				570 570 570 570
				570 570 570 570
				570 570 570 570
				570 570 570 570
				570 570 570 570
				570 570 570 570
				570 570 570 570
				570 570 570 570
				570 570 570 570
				570 570 570 570
				570 570 570 570
				570 570 570 570
				570 570 570 570
				570 570 570 570
				570 570 570 570
				570 570 570 570
				570 570 570 570
				570 570 570 570
				570 570 570 570
				570 570 570 570
				570 570 570 570
				570 570 570 570
				570 570 570 570
				570 570 570 570
				570 570 570 570
				570 570 570 570
				570 570 570 570
				570 570 570 570
				570 570 570 570>;

			PS_Config_Lmt_PenRingY_FW_Raw_N = <
				(-570) (-570) (-570) (-570)
				(-570) (-570) (-570) (-570)
				(-570) (-570) (-570) (-570)
				(-570) (-570) (-570) (-570)
				(-570) (-570) (-570) (-570)
				(-570) (-570) (-570) (-570)
				(-570) (-570) (-570) (-570)
				(-570) (-570) (-570) (-570)
				(-570) (-570) (-570) (-570)
				(-570) (-570) (-570) (-570)
				(-570) (-570) (-570) (-570)
				(-570) (-570) (-570) (-570)
				(-570) (-570) (-570) (-570)
				(-570) (-570) (-570) (-570)
				(-570) (-570) (-570) (-570)
				(-570) (-570) (-570) (-570)
				(-570) (-570) (-570) (-570)
				(-570) (-570) (-570) (-570)
				(-570) (-570) (-570) (-570)
				(-570) (-570) (-570) (-570)
				(-570) (-570) (-570) (-570)
				(-570) (-570) (-570) (-570)
				(-570) (-570) (-570) (-570)
				(-570) (-570) (-570) (-570)
				(-570) (-570) (-570) (-570)
				(-570) (-570) (-570) (-570)
				(-570) (-570) (-570) (-570)
				(-570) (-570) (-570) (-570)
				(-570) (-570) (-570) (-570)
				(-570) (-570) (-570) (-570)
				(-570) (-570) (-570) (-570)
				(-570) (-570) (-570) (-570)
				(-570) (-570) (-570) (-570)
				(-570) (-570) (-570) (-570)
				(-570) (-570) (-570) (-570)
				(-570) (-570) (-570) (-570)
				(-570) (-570) (-570) (-570)
				(-570) (-570) (-570) (-570)
				(-570) (-570) (-570) (-570)
				(-570) (-570) (-570) (-570)
				(-570) (-570) (-570) (-570)
				(-570) (-570) (-570) (-570)
				(-570) (-570) (-570) (-570)
				(-570) (-570) (-570) (-570)
				(-570) (-570) (-570) (-570)
				(-570) (-570) (-570) (-570)
				(-570) (-570) (-570) (-570)
				(-570) (-570) (-570) (-570)
				(-570) (-570) (-570) (-570)
				(-570) (-570) (-570) (-570)>;

			PS_Config_Lmt_PenTipX_FW_Diff_P = <
				870 870 870 870 870 870 870 870 870 870 870 870 870 870 870 870 870 870 870 870 870 870 870 870 870 870 870 870 870 870 870 870
				870 870 870 870 870 870 870 870 870 870 870 870 870 870 870 870 870 870 870 870 870 870 870 870 870 870 870 870 870 870 870 870
				870 870 870 870 870 870 870 870 870 870 870 870 870 870 870 870 870 870 870 870 870 870 870 870 870 870 870 870 870 870 870 870
				870 870 870 870 870 870 870 870 870 870 870 870 870 870 870 870 870 870 870 870 870 870 870 870 870 870 870 870 870 870 870 870
				870 870 870 870 870 870 870 870 870 870 870 870 870 870 870 870 870 870 870 870 870 870 870 870 870 870 870 870 870 870 870 870
				870 870 870 870 870 870 870 870 870 870 870 870 870 870 870 870 870 870 870 870 870 870 870 870 870 870 870 870 870 870 870 870>;

			PS_Config_Lmt_PenTipX_FW_Diff_N = <
				(-870) (-870) (-870) (-870) (-870) (-870) (-870) (-870) (-870) (-870) (-870) (-870) (-870) (-870) (-870) (-870) (-870) (-870) (-870) (-870) (-870) (-870) (-870) (-870) (-870) (-870) (-870) (-870) (-870) (-870) (-870) (-870)
				(-870) (-870) (-870) (-870) (-870) (-870) (-870) (-870) (-870) (-870) (-870) (-870) (-870) (-870) (-870) (-870) (-870) (-870) (-870) (-870) (-870) (-870) (-870) (-870) (-870) (-870) (-870) (-870) (-870) (-870) (-870) (-870)
				(-870) (-870) (-870) (-870) (-870) (-870) (-870) (-870) (-870) (-870) (-870) (-870) (-870) (-870) (-870) (-870) (-870) (-870) (-870) (-870) (-870) (-870) (-870) (-870) (-870) (-870) (-870) (-870) (-870) (-870) (-870) (-870)
				(-870) (-870) (-870) (-870) (-870) (-870) (-870) (-870) (-870) (-870) (-870) (-870) (-870) (-870) (-870) (-870) (-870) (-870) (-870) (-870) (-870) (-870) (-870) (-870) (-870) (-870) (-870) (-870) (-870) (-870) (-870) (-870)
				(-870) (-870) (-870) (-870) (-870) (-870) (-870) (-870) (-870) (-870) (-870) (-870) (-870) (-870) (-870) (-870) (-870) (-870) (-870) (-870) (-870) (-870) (-870) (-870) (-870) (-870) (-870) (-870) (-870) (-870) (-870) (-870)
				(-870) (-870) (-870) (-870) (-870) (-870) (-870) (-870) (-870) (-870) (-870) (-870) (-870) (-870) (-870) (-870) (-870) (-870) (-870) (-870) (-870) (-870) (-870) (-870) (-870) (-870) (-870) (-870) (-870) (-870) (-870) (-870)>;

			PS_Config_Lmt_PenTipY_FW_Diff_P = <
				870 870 870 870
				870 870 870 870
				870 870 870 870
				870 870 870 870
				870 870 870 870
				870 870 870 870
				870 870 870 870
				870 870 870 870
				870 870 870 870
				870 870 870 870
				870 870 870 870
				870 870 870 870
				870 870 870 870
				870 870 870 870
				870 870 870 870
				870 870 870 870
				870 870 870 870
				870 870 870 870
				870 870 870 870
				870 870 870 870
				870 870 870 870
				870 870 870 870
				870 870 870 870
				870 870 870 870
				870 870 870 870
				870 870 870 870
				870 870 870 870
				870 870 870 870
				870 870 870 870
				870 870 870 870
				870 870 870 870
				870 870 870 870
				870 870 870 870
				870 870 870 870
				870 870 870 870
				870 870 870 870
				870 870 870 870
				870 870 870 870
				870 870 870 870
				870 870 870 870
				870 870 870 870
				870 870 870 870
				870 870 870 870
				870 870 870 870
				870 870 870 870
				870 870 870 870
				870 870 870 870
				870 870 870 870
				870 870 870 870
				870 870 870 870>;

			PS_Config_Lmt_PenTipY_FW_Diff_N = <
				(-870) (-870) (-870) (-870)
				(-870) (-870) (-870) (-870)
				(-870) (-870) (-870) (-870)
				(-870) (-870) (-870) (-870)
				(-870) (-870) (-870) (-870)
				(-870) (-870) (-870) (-870)
				(-870) (-870) (-870) (-870)
				(-870) (-870) (-870) (-870)
				(-870) (-870) (-870) (-870)
				(-870) (-870) (-870) (-870)
				(-870) (-870) (-870) (-870)
				(-870) (-870) (-870) (-870)
				(-870) (-870) (-870) (-870)
				(-870) (-870) (-870) (-870)
				(-870) (-870) (-870) (-870)
				(-870) (-870) (-870) (-870)
				(-870) (-870) (-870) (-870)
				(-870) (-870) (-870) (-870)
				(-870) (-870) (-870) (-870)
				(-870) (-870) (-870) (-870)
				(-870) (-870) (-870) (-870)
				(-870) (-870) (-870) (-870)
				(-870) (-870) (-870) (-870)
				(-870) (-870) (-870) (-870)
				(-870) (-870) (-870) (-870)
				(-870) (-870) (-870) (-870)
				(-870) (-870) (-870) (-870)
				(-870) (-870) (-870) (-870)
				(-870) (-870) (-870) (-870)
				(-870) (-870) (-870) (-870)
				(-870) (-870) (-870) (-870)
				(-870) (-870) (-870) (-870)
				(-870) (-870) (-870) (-870)
				(-870) (-870) (-870) (-870)
				(-870) (-870) (-870) (-870)
				(-870) (-870) (-870) (-870)
				(-870) (-870) (-870) (-870)
				(-870) (-870) (-870) (-870)
				(-870) (-870) (-870) (-870)
				(-870) (-870) (-870) (-870)
				(-870) (-870) (-870) (-870)
				(-870) (-870) (-870) (-870)
				(-870) (-870) (-870) (-870)
				(-870) (-870) (-870) (-870)
				(-870) (-870) (-870) (-870)
				(-870) (-870) (-870) (-870)
				(-870) (-870) (-870) (-870)
				(-870) (-870) (-870) (-870)
				(-870) (-870) (-870) (-870)
				(-870) (-870) (-870) (-870)>;

			PS_Config_Lmt_PenRingX_FW_Diff_P = <
				870 870 870 870 870 870 870 870 870 870 870 870 870 870 870 870 870 870 870 870 870 870 870 870 870 870 870 870 870 870 870 870
				870 870 870 870 870 870 870 870 870 870 870 870 870 870 870 870 870 870 870 870 870 870 870 870 870 870 870 870 870 870 870 870
				870 870 870 870 870 870 870 870 870 870 870 870 870 870 870 870 870 870 870 870 870 870 870 870 870 870 870 870 870 870 870 870
				870 870 870 870 870 870 870 870 870 870 870 870 870 870 870 870 870 870 870 870 870 870 870 870 870 870 870 870 870 870 870 870
				870 870 870 870 870 870 870 870 870 870 870 870 870 870 870 870 870 870 870 870 870 870 870 870 870 870 870 870 870 870 870 870
				870 870 870 870 870 870 870 870 870 870 870 870 870 870 870 870 870 870 870 870 870 870 870 870 870 870 870 870 870 870 870 870>;

			PS_Config_Lmt_PenRingX_FW_Diff_N = <
				(-870) (-870) (-870) (-870) (-870) (-870) (-870) (-870) (-870) (-870) (-870) (-870) (-870) (-870) (-870) (-870) (-870) (-870) (-870) (-870) (-870) (-870) (-870) (-870) (-870) (-870) (-870) (-870) (-870) (-870) (-870) (-870)
				(-870) (-870) (-870) (-870) (-870) (-870) (-870) (-870) (-870) (-870) (-870) (-870) (-870) (-870) (-870) (-870) (-870) (-870) (-870) (-870) (-870) (-870) (-870) (-870) (-870) (-870) (-870) (-870) (-870) (-870) (-870) (-870)
				(-870) (-870) (-870) (-870) (-870) (-870) (-870) (-870) (-870) (-870) (-870) (-870) (-870) (-870) (-870) (-870) (-870) (-870) (-870) (-870) (-870) (-870) (-870) (-870) (-870) (-870) (-870) (-870) (-870) (-870) (-870) (-870)
				(-870) (-870) (-870) (-870) (-870) (-870) (-870) (-870) (-870) (-870) (-870) (-870) (-870) (-870) (-870) (-870) (-870) (-870) (-870) (-870) (-870) (-870) (-870) (-870) (-870) (-870) (-870) (-870) (-870) (-870) (-870) (-870)
				(-870) (-870) (-870) (-870) (-870) (-870) (-870) (-870) (-870) (-870) (-870) (-870) (-870) (-870) (-870) (-870) (-870) (-870) (-870) (-870) (-870) (-870) (-870) (-870) (-870) (-870) (-870) (-870) (-870) (-870) (-870) (-870)
				(-870) (-870) (-870) (-870) (-870) (-870) (-870) (-870) (-870) (-870) (-870) (-870) (-870) (-870) (-870) (-870) (-870) (-870) (-870) (-870) (-870) (-870) (-870) (-870) (-870) (-870) (-870) (-870) (-870) (-870) (-870) (-870)>;

			PS_Config_Lmt_PenRingY_FW_Diff_P = <
				870 870 870 870
				870 870 870 870
				870 870 870 870
				870 870 870 870
				870 870 870 870
				870 870 870 870
				870 870 870 870
				870 870 870 870
				870 870 870 870
				870 870 870 870
				870 870 870 870
				870 870 870 870
				870 870 870 870
				870 870 870 870
				870 870 870 870
				870 870 870 870
				870 870 870 870
				870 870 870 870
				870 870 870 870
				870 870 870 870
				870 870 870 870
				870 870 870 870
				870 870 870 870
				870 870 870 870
				870 870 870 870
				870 870 870 870
				870 870 870 870
				870 870 870 870
				870 870 870 870
				870 870 870 870
				870 870 870 870
				870 870 870 870
				870 870 870 870
				870 870 870 870
				870 870 870 870
				870 870 870 870
				870 870 870 870
				870 870 870 870
				870 870 870 870
				870 870 870 870
				870 870 870 870
				870 870 870 870
				870 870 870 870
				870 870 870 870
				870 870 870 870
				870 870 870 870
				870 870 870 870
				870 870 870 870
				870 870 870 870
				870 870 870 870>;

			PS_Config_Lmt_PenRingY_FW_Diff_N = <
				(-870) (-870) (-870) (-870)
				(-870) (-870) (-870) (-870)
				(-870) (-870) (-870) (-870)
				(-870) (-870) (-870) (-870)
				(-870) (-870) (-870) (-870)
				(-870) (-870) (-870) (-870)
				(-870) (-870) (-870) (-870)
				(-870) (-870) (-870) (-870)
				(-870) (-870) (-870) (-870)
				(-870) (-870) (-870) (-870)
				(-870) (-870) (-870) (-870)
				(-870) (-870) (-870) (-870)
				(-870) (-870) (-870) (-870)
				(-870) (-870) (-870) (-870)
				(-870) (-870) (-870) (-870)
				(-870) (-870) (-870) (-870)
				(-870) (-870) (-870) (-870)
				(-870) (-870) (-870) (-870)
				(-870) (-870) (-870) (-870)
				(-870) (-870) (-870) (-870)
				(-870) (-870) (-870) (-870)
				(-870) (-870) (-870) (-870)
				(-870) (-870) (-870) (-870)
				(-870) (-870) (-870) (-870)
				(-870) (-870) (-870) (-870)
				(-870) (-870) (-870) (-870)
				(-870) (-870) (-870) (-870)
				(-870) (-870) (-870) (-870)
				(-870) (-870) (-870) (-870)
				(-870) (-870) (-870) (-870)
				(-870) (-870) (-870) (-870)
				(-870) (-870) (-870) (-870)
				(-870) (-870) (-870) (-870)
				(-870) (-870) (-870) (-870)
				(-870) (-870) (-870) (-870)
				(-870) (-870) (-870) (-870)
				(-870) (-870) (-870) (-870)
				(-870) (-870) (-870) (-870)
				(-870) (-870) (-870) (-870)
				(-870) (-870) (-870) (-870)
				(-870) (-870) (-870) (-870)
				(-870) (-870) (-870) (-870)
				(-870) (-870) (-870) (-870)
				(-870) (-870) (-870) (-870)
				(-870) (-870) (-870) (-870)
				(-870) (-870) (-870) (-870)
				(-870) (-870) (-870) (-870)
				(-870) (-870) (-870) (-870)
				(-870) (-870) (-870) (-870)
				(-870) (-870) (-870) (-870)>;

			PS_Config_Diff_Test_Frame = <50>;
		};
	};
};
